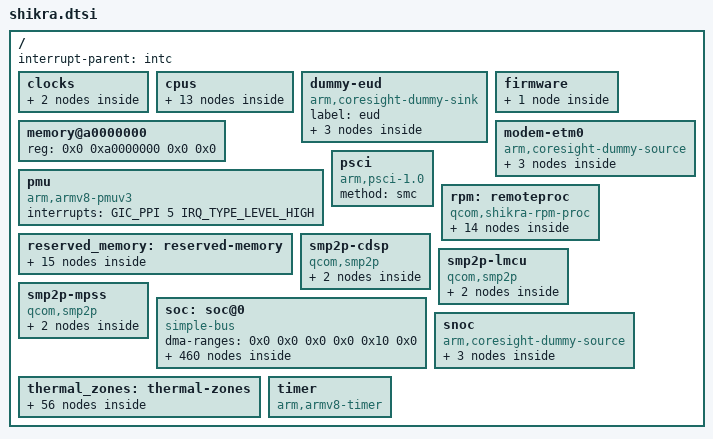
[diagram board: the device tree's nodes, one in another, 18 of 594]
// SPDX-License-Identifier: BSD-3-Clause
/*
 * Copyright (c) Qualcomm Technologies, Inc. and/or its subsidiaries.
 */

#include <dt-bindings/clock/qcom,rpmcc.h>
#include <dt-bindings/clock/qcom,dsi-phy-28nm.h>
#include <dt-bindings/clock/qcom,shikra-dispcc.h>
#include <dt-bindings/clock/qcom,shikra-gcc.h>
#include <dt-bindings/clock/qcom,shikra-gpucc.h>
#include <dt-bindings/interconnect/qcom,icc.h>
#include <dt-bindings/dma/qcom-gpi.h>
#include <dt-bindings/interconnect/qcom,rpm-icc.h>
#include <dt-bindings/interconnect/qcom,shikra.h>
#include <dt-bindings/interrupt-controller/arm-gic.h>
#include <dt-bindings/power/qcom-rpmpd.h>
#include <dt-bindings/thermal/thermal.h>

/ {
	interrupt-parent = <&intc>;

	#address-cells = <2>;
	#size-cells = <2>;

	clocks {
		xo_board: xo-board {
			compatible = "fixed-clock";
			clock-frequency = <38400000>;
			#clock-cells = <0>;
		};

		sleep_clk: sleep-clk {
			compatible = "fixed-clock";
			clock-frequency = <32764>;
			#clock-cells = <0>;
		};
	};

	cpus {
		#address-cells = <2>;
		#size-cells = <0>;

		cpu0: cpu@0 {
			device_type = "cpu";
			compatible = "arm,cortex-a55";
			reg = <0x0 0x0>;
			enable-method = "psci";
			next-level-cache = <&l3>;
			capacity-dmips-mhz = <1024>;
			dynamic-power-coefficient = <100>;
			qcom,freq-domain = <&cpufreq_hw 0>;
			#cooling-cells = <2>;
		};

		cpu1: cpu@100 {
			device_type = "cpu";
			compatible = "arm,cortex-a55";
			reg = <0x0 0x100>;
			enable-method = "psci";
			next-level-cache = <&l3>;
			capacity-dmips-mhz = <1024>;
			dynamic-power-coefficient = <100>;
			qcom,freq-domain = <&cpufreq_hw 0>;
			#cooling-cells = <2>;
		};

		cpu2: cpu@200 {
			device_type = "cpu";
			compatible = "arm,cortex-a55";
			reg = <0x0 0x200>;
			enable-method = "psci";
			next-level-cache = <&l3>;
			capacity-dmips-mhz = <1024>;
			dynamic-power-coefficient = <100>;
			qcom,freq-domain = <&cpufreq_hw 0>;
			#cooling-cells = <2>;
		};

		cpu3: cpu@300 {
			device_type = "cpu";
			compatible = "arm,cortex-a78c";
			reg = <0x0 0x300>;
			enable-method = "psci";
			next-level-cache = <&l2_3>;
			capacity-dmips-mhz = <1946>;
			dynamic-power-coefficient = <486>;
			qcom,freq-domain = <&cpufreq_hw 1>;
			#cooling-cells = <2>;

			l2_3: l2-cache {
				compatible = "cache";
				cache-level = <2>;
				cache-unified;
				next-level-cache = <&l3>;
			};
		};

		cpu-map {
			cluster0 {
				core0 {
					cpu = <&cpu0>;
				};

				core1 {
					cpu = <&cpu1>;
				};

				core2 {
					cpu = <&cpu2>;
				};
			};

			cluster1 {
				core0 {
					cpu = <&cpu3>;
				};
			};
		};

		l3: l3-cache {
			compatible = "cache";
			cache-level = <3>;
			cache-unified;
		};
	};

	dummy-eud {
		compatible = "arm,coresight-dummy-sink";

		label = "eud";

		in-ports {
			port {
				eud_in: endpoint {
					remote-endpoint = <&replicator_eud_out1>;
				};
			};
		};
	};

	firmware {
		scm {
			compatible = "qcom,scm-shikra", "qcom,scm";
			qcom,dload-mode = <&tcsr_regs 0x13000>;
			interconnects = <&system_noc MASTER_CRYPTO_CORE0 RPM_ALWAYS_TAG
					 &mc_virt SLAVE_EBI_CH0 RPM_ALWAYS_TAG>;
		};
	};

	memory@a0000000 {
		device_type = "memory";
		/* We expect the bootloader to fill in the size */
		reg = <0x0 0xa0000000 0x0 0x0>;
	};

	modem-etm0 {
		compatible = "arm,coresight-dummy-source";

		label = "modem_etm0";
		arm,static-trace-id = <36>;

		out-ports {
			port {
				modem_etm0_out: endpoint {
					remote-endpoint = <&funnel_in1_in4>;
				};
			};
		};
	};

	pmu {
		compatible = "arm,armv8-pmuv3";
		interrupts = <GIC_PPI 5 IRQ_TYPE_LEVEL_HIGH>;
	};

	psci {
		compatible = "arm,psci-1.0";
		method = "smc";
	};

	rpm: remoteproc {
		compatible = "qcom,shikra-rpm-proc", "qcom,rpm-proc";

		glink-edge {
			compatible = "qcom,glink-rpm";
			interrupts = <GIC_SPI 194 IRQ_TYPE_EDGE_RISING>;
			qcom,rpm-msg-ram = <&rpm_msg_ram>;
			mboxes = <&apcs_glb 0>;

			rpm_requests: rpm-requests {
				compatible = "qcom,rpm-shikra", "qcom,glink-smd-rpm";
				qcom,glink-channels = "rpm_requests";

				rpmcc: clock-controller {
					compatible = "qcom,rpmcc-shikra", "qcom,rpmcc";
					clocks = <&xo_board>;
					clock-names = "xo";
					#clock-cells = <1>;
				};

				rpmpd: power-controller {
					compatible = "qcom,shikra-rpmpd";
					#power-domain-cells = <1>;
					operating-points-v2 = <&rpmpd_opp_table>;

					rpmpd_opp_table: opp-table {
						compatible = "operating-points-v2";

						rpmpd_opp_min_svs: opp1 {
							opp-level = <RPM_SMD_LEVEL_MIN_SVS>;
						};

						rpmpd_opp_low_svs: opp2 {
							opp-level = <RPM_SMD_LEVEL_LOW_SVS>;
						};

						rpmpd_opp_svs: opp3 {
							opp-level = <RPM_SMD_LEVEL_SVS>;
						};

						rpmpd_opp_svs_plus: opp4 {
							opp-level = <RPM_SMD_LEVEL_SVS_PLUS>;
						};

						rpmpd_opp_nom: opp5 {
							opp-level = <RPM_SMD_LEVEL_NOM>;
						};

						rpmpd_opp_nom_plus: opp6 {
							opp-level = <RPM_SMD_LEVEL_NOM_PLUS>;
						};

						rpmpd_opp_turbo: opp7 {
							opp-level = <RPM_SMD_LEVEL_TURBO>;
						};

						rpmpd_opp_turbo_plus: opp8 {
							opp-level = <RPM_SMD_LEVEL_TURBO_NO_CPR>;
						};
					};
				};
			};
		};

		mpm: interrupt-controller {
			compatible = "qcom,mpm";
			qcom,rpm-msg-ram = <&apss_mpm>;
			interrupts = <GIC_SPI 197 IRQ_TYPE_EDGE_RISING>;
			mboxes = <&apcs_glb 1>;
			interrupt-controller;
			#interrupt-cells = <2>;
			#power-domain-cells = <0>;
			interrupt-parent = <&intc>;
			qcom,mpm-pin-count = <96>;
			qcom,mpm-pin-map = <2 275>,  /* TSENS0 uplow */
					   <12 422>, /* DWC3 ss_phy_irq */
					   <58 272>, /* QUSB2_PHY dmse_hv_vddmx */
					   <59 273>, /* QUSB2_PHY dpse_hv_vddmx */
					   <86 183>, /* MPM wake, SPMI */
					   <90 157>, /* QUSB2_PHY DM */
					   <91 158>; /* QUSB2_PHY DP */
		};
	};

	reserved_memory: reserved-memory {
		#address-cells = <2>;
		#size-cells = <2>;
		ranges;

		hyp_mem: hyp@80000000 {
			reg = <0x0 0x80000000 0x0 0x1600000>;
			no-map;
		};

		xblboot_mem: xblboot@85e00000 {
			reg = <0x0 0x85e00000 0x0 0x100000>;
			no-map;
		};

		secdata_apss_mem: secdata-apss@85fff000 {
			reg = <0x0 0x85fff000 0x0 0x1000>;
			no-map;
		};

		smem_mem: smem_region@86000000 {
			compatible = "qcom,smem";
			reg = <0x0 0x86000000 0x0 0x200000>;
			no-map;

			hwlocks = <&tcsr_mutex 3>;
		};

		audio_heap_mem: audio-heap@86200000 {
			reg = <0x0 0x86200000 0x0 0x100000>;
			no-map;
		};

		tz_stat_mem: tz-stat@a0000000 {
			reg = <0x0 0xa0000000 0x0 0x100000>;
			no-map;
		};

		qtee_mem: qtee@a1300000 {
			reg = <0x0 0xa1300000 0x0 0x500000>;
			no-map;
		};

		tz_apps_mem: tz-apps@a1800000 {
			reg = <0x0 0xa1800000 0x0 0x2100000>;
			no-map;
		};

		mpss_wlan_mem: mpss-wlan@ab000000 {
			reg = <0x0 0xab000000 0x0 0x6e00000>;
			no-map;
		};

		wlan_mem: wlan@b2300000 {
			reg = <0x0 0xb2300000 0x0 0x100000>;
			no-map;
		};

		cdsp_mem: cdsp@b2400000 {
			reg = <0x0 0xb2400000 0x0 0x1900000>;
			no-map;
		};

		gpu_micro_code_mem: gpu-micro-code@b3d00000 {
			reg = <0x0 0xb3d00000 0x0 0x2000>;
			no-map;
		};

		video_mem: video@b3d02000 {
			reg = <0x0 0xb3d02000 0x0 0x700000>;
			no-map;
		};

		lmcu_mem: lmcu@b4402000 {
			reg = <0x0 0xb4402000 0x0 0x300000>;
			no-map;
		};

		lmcu_dtb_mem: lmcu-dtb@b4702000 {
			reg = <0x0 0xb4702000 0x0 0x40000>;
			no-map;
		};

	};

	smp2p-cdsp {
		compatible = "qcom,smp2p";
		qcom,smem = <94>, <432>;

		interrupts = <GIC_SPI 263 IRQ_TYPE_EDGE_RISING>;

		mboxes = <&apcs_glb 6>;

		qcom,local-pid = <0>;
		qcom,remote-pid = <5>;

		cdsp_smp2p_out: master-kernel {
			qcom,entry-name = "master-kernel";
			#qcom,smem-state-cells = <1>;
		};

		cdsp_smp2p_in: slave-kernel {
			qcom,entry-name = "slave-kernel";
			interrupt-controller;
			#interrupt-cells = <2>;
		};
	};

	smp2p-lmcu {
		compatible = "qcom,smp2p";
		qcom,smem = <617>, <616>;

		interrupts = <GIC_SPI 287 IRQ_TYPE_EDGE_RISING>;

		mboxes = <&apcs_glb 10>;

		qcom,local-pid = <0>;
		qcom,remote-pid = <26>;

		lmcu_smp2p_out: master-kernel {
			qcom,entry-name = "master-kernel";
			#qcom,smem-state-cells = <1>;
		};

		lmcu_smp2p_in: slave-kernel {
			qcom,entry-name = "slave-kernel";
			interrupt-controller;
			#interrupt-cells = <2>;
		};
	};

	smp2p-mpss {
		compatible = "qcom,smp2p";
		qcom,smem = <435>, <428>;

		interrupts = <GIC_SPI 70 IRQ_TYPE_EDGE_RISING>;

		mboxes = <&apcs_glb 14>;

		qcom,local-pid = <0>;
		qcom,remote-pid = <1>;

		modem_smp2p_out: master-kernel {
			qcom,entry-name = "master-kernel";
			#qcom,smem-state-cells = <1>;
		};

		modem_smp2p_in: slave-kernel {
			qcom,entry-name = "slave-kernel";
			interrupt-controller;
			#interrupt-cells = <2>;
		};
	};

	soc: soc@0 {
		compatible = "simple-bus";

		#address-cells = <2>;
		#size-cells = <2>;
		dma-ranges = <0x0 0x0 0x0 0x0 0x10 0x0>;
		ranges = <0x0 0x0 0x0 0x0 0x10 0x0>;

		tcsr_mutex: syscon@340000 {
			compatible = "qcom,tcsr-mutex";
			reg = <0x0 0x00340000 0x0 0x20000>;
			#hwlock-cells = <1>;
		};

		tcsr_regs: syscon@3c0000 {
			compatible = "qcom,shikra-tcsr", "syscon";
			reg = <0x0 0x003c0000 0x0 0x40000>;
		};

		tlmm: pinctrl@500000 {
			compatible = "qcom,shikra-tlmm";
			reg = <0x0 0x00500000 0x0 0x800000>;

			interrupts = <GIC_SPI 227 IRQ_TYPE_LEVEL_HIGH>;

			gpio-controller;
			#gpio-cells = <2>;

			interrupt-controller;
			#interrupt-cells = <2>;

			gpio-ranges = <&tlmm 0 0 165>;
			wakeup-parent = <&mpm>;

			qup_i2c0_data_clk: qup-i2c0-data-clk-state {
				/* SDA, SCL */
				pins = "gpio2", "gpio3";
				function = "qup0_se0";
				drive-strength = <2>;
				bias-pull-up;
			};

			qup_i2c1_data_clk: qup-i2c1-data-clk-state {
				/* SDA, SCL */
				pins = "gpio4", "gpio5";
				function = "qup0_se1_01";
				drive-strength = <2>;
				bias-pull-up;
			};

			qup_i2c2_data_clk: qup-i2c2-data-clk-state {
				/* SDA, SCL */
				pins = "gpio6", "gpio7";
				function = "qup0_se2";
				drive-strength = <2>;
				bias-pull-up;
			};

			qup_i2c3_data_clk: qup-i2c3-data-clk-state {
				/* SDA, SCL */
				pins = "gpio10", "gpio11";
				function = "qup0_se3_01";
				drive-strength = <2>;
				bias-pull-up;
			};

			qup_i2c4_data_clk: qup-i2c4-data-clk-state {
				/* SDA, SCL */
				pins = "gpio12", "gpio13";
				function = "qup0_se4_01";
				drive-strength = <2>;
				bias-pull-up;
			};

			qup_i2c5_data_clk: qup-i2c5-data-clk-state {
				/* SDA, SCL */
				pins = "gpio14", "gpio15";
				function = "qup0_se5";
				drive-strength = <2>;
				bias-pull-up;
			};

			qup_i2c6_data_clk: qup-i2c6-data-clk-state {
				/* SDA, SCL */
				pins = "gpio18", "gpio19";
				function = "qup0_se6";
				drive-strength = <2>;
				bias-pull-up;
			};

			qup_i2c7_data_clk: qup-i2c7-data-clk-state {
				/* SDA, SCL */
				pins = "gpio20", "gpio21";
				function = "qup0_se7_01";
				drive-strength = <2>;
				bias-pull-up;
			};

			qup_i2c8_data_clk: qup-i2c8-data-clk-state {
				/* SDA, SCL */
				pins = "gpio22", "gpio23";
				function = "qup0_se8";
				drive-strength = <2>;
				bias-pull-up;
			};

			qup_i2c9_data_clk: qup-i2c9-data-clk-state {
				/* SDA, SCL */
				pins = "gpio27", "gpio26";
				function = "qup0_se9_01";
				drive-strength = <2>;
				bias-pull-up;
			};

			qup_spi0_cs: qup-spi0-cs-state {
				pins = "gpio1";
				function = "qup0_se0";
				drive-strength = <6>;
				bias-disable;
			};

			qup_spi0_data_clk: qup-spi0-data-clk-state {
				/* MISO, MOSI, CLK */
				pins = "gpio2", "gpio3", "gpio0";
				function = "qup0_se0";
				drive-strength = <6>;
				bias-disable;
			};

			qup_spi2_cs: qup-spi2-cs-state {
				pins = "gpio9";
				function = "qup0_se2";
				drive-strength = <6>;
				bias-disable;
			};

			qup_spi2_data_clk: qup-spi2-data-clk-state {
				/* MISO, MOSI, CLK */
				pins = "gpio6", "gpio7", "gpio8";
				function = "qup0_se2";
				drive-strength = <6>;
				bias-disable;
			};

			qup_spi5_cs: qup-spi5-cs-state {
				pins = "gpio17";
				function = "qup0_se5";
				drive-strength = <6>;
				bias-disable;
			};

			qup_spi5_data_clk: qup-spi5-data-clk-state {
				/* MISO, MOSI, CLK */
				pins = "gpio14", "gpio15", "gpio16";
				function = "qup0_se5";
				drive-strength = <6>;
				bias-disable;
			};

			qup_spi6_cs: qup-spi6-cs-state {
				pins = "gpio29";
				function = "qup0_se6";
				drive-strength = <6>;
				bias-disable;
			};

			qup_spi6_data_clk: qup-spi6-data-clk-state {
				/* MISO, MOSI, CLK */
				pins = "gpio18", "gpio19", "gpio28";
				function = "qup0_se6";
				drive-strength = <6>;
				bias-disable;
			};

			qup_spi8_cs: qup-spi8-cs-state {
				pins = "gpio25";
				function = "qup0_se8";
				drive-strength = <6>;
				bias-disable;
			};

			qup_spi8_data_clk: qup-spi8-data-clk-state {
				/* MISO, MOSI, CLK */
				pins = "gpio22", "gpio23", "gpio24";
				function = "qup0_se8";
				drive-strength = <6>;
				bias-disable;
			};

			qup_uart0_default: qup-uart0-default-state {
				pins = "gpio0", "gpio1";
				function = "qup0_se0";
				drive-strength = <2>;
				bias-disable;
			};

			qup_uart1_default: qup-uart1-default-state {
				pins = "gpio4", "gpio5";
				function = "qup0_se1_23";
				drive-strength = <2>;
				bias-disable;
			};

			qup_uart2_default: qup-uart2-default-state {
				/* TX, RX */
				pins = "gpio8", "gpio9";
				function = "qup0_se2";
				drive-strength = <2>;
				bias-pull-up;
			};

			qup_uart2_cts_rts: qup-uart2-cts-rts-state {
				/* CTS, RTS */
				pins = "gpio6", "gpio7";
				function = "qup0_se2";
				drive-strength = <2>;
				bias-pull-down;
			};

			qup_uart3_default: qup-uart3-default-state {
				pins = "gpio10", "gpio11";
				function = "qup0_se3_23";
				drive-strength = <2>;
				bias-disable;
			};

			qup_uart4_default: qup-uart4-default-state {
				pins = "gpio12", "gpio13";
				function = "qup0_se4_23";
				drive-strength = <2>;
				bias-disable;
			};

			qup_uart5_default: qup-uart5-default-state {
				/* TX, RX */
				pins = "gpio16", "gpio17";
				function = "qup0_se5";
				drive-strength = <2>;
				bias-pull-up;
			};

			qup_uart5_cts_rts: qup-uart5-cts-rts-state {
				/* CTS, RTS */
				pins = "gpio14", "gpio15";
				function = "qup0_se5";
				drive-strength = <2>;
				bias-pull-down;
			};

			qup_uart6_default: qup-uart6-default-state {
				/* TX, RX */
				pins = "gpio28", "gpio29";
				function = "qup0_se6";
				drive-strength = <2>;
				bias-pull-up;
			};

			qup_uart6_cts_rts: qup-uart6-cts-rts-state {
				/* CTS, RTS */
				pins = "gpio18", "gpio19";
				function = "qup0_se6";
				drive-strength = <2>;
				bias-pull-down;
			};

			qup_uart7_default: qup-uart7-default-state {
				pins = "gpio20", "gpio21";
				function = "qup0_se7_23";
				drive-strength = <2>;
				bias-disable;
			};

			qup_uart8_default: qup-uart8-default-state {
				/* TX, RX */
				pins = "gpio24", "gpio25";
				function = "qup0_se8";
				drive-strength = <2>;
				bias-pull-up;
			};

			qup_uart8_cts_rts: qup-uart8-cts-rts-state {
				/* CTS, RTS */
				pins = "gpio22", "gpio23";
				function = "qup0_se8";
				drive-strength = <2>;
				bias-pull-down;
			};

			qup_uart9_default: qup-uart9-default-state {
				pins = "gpio26", "gpio27";
				function = "qup0_se9_23";
				drive-strength = <2>;
				bias-disable;
			};

			sdc1_state_on: sdc1-on-state {
				clk-pins {
					pins = "sdc1_clk";
					drive-strength = <6>;
					bias-disable;
				};

				cmd-pins {
					pins = "sdc1_cmd";
					drive-strength = <6>;
					bias-pull-up;
				};

				data-pins {
					pins = "sdc1_data";
					drive-strength = <6>;
					bias-pull-up;
				};

				rclk-pins {
					pins = "sdc1_rclk";
					bias-pull-down;
				};
			};

			sdc1_state_off: sdc1-off-state {
				clk-pins {
					pins = "sdc1_clk";
					drive-strength = <2>;
					bias-bus-hold;
				};

				cmd-pins {
					pins = "sdc1_cmd";
					drive-strength = <2>;
					bias-bus-hold;
				};

				data-pins {
					pins = "sdc1_data";
					drive-strength = <2>;
					bias-bus-hold;
				};

				rclk-pins {
					pins = "sdc1_rclk";
					bias-bus-hold;
				};
			};

			sdc2_default: sdc2-default-state {
				clk-pins {
					pins = "sdc2_clk";
					drive-strength = <14>;
					bias-disable;
				};

				cmd-pins {
					pins = "sdc2_cmd";
					drive-strength = <14>;
					bias-pull-up;
				};

				data-pins {
					pins = "sdc2_data";
					drive-strength = <14>;
					bias-pull-up;
				};
			};

			sdc2_sleep: sdc2-sleep-state {
				clk-pins {
					pins = "sdc2_clk";
					drive-strength = <2>;
					bias-disable;
				};

				cmd-pins {
					pins = "sdc2_cmd";
					drive-strength = <2>;
					bias-pull-up;
				};

				data-pins {
					pins = "sdc2_data";
					drive-strength = <2>;
					bias-pull-up;
				};
			};

			sdc2_card_det_n: sd-card-det-n-state {
				pins = "gpio89";
				function = "gpio";
				drive-strength = <2>;
				bias-pull-up;
			};
		};

		mem_noc: interconnect@d00000 {
			compatible = "qcom,shikra-mem-noc-core";
			reg = <0x0 0x00d00000 0x0 0x43080>;
			clocks = <&gcc GCC_DDRSS_GPU_AXI_CLK>;
			clock-names = "gpu_axi";
			#interconnect-cells = <2>;
		};

		llcc: system-cache-controller@e00000 {
			compatible = "qcom,shikra-llcc";
			reg = <0x0 0x00e00000 0x0 0x80000>,
			      <0x0 0x0f00000 0x0 0x80000>,
			      <0x0 0x1000000 0x0 0x80000>;
			reg-names = "llcc0_base", "llcc1_base", "llcc_broadcast_base";
			interrupts = <GIC_SPI 571 IRQ_TYPE_LEVEL_HIGH>;
		};

		gcc: clock-controller@1400000 {
			compatible = "qcom,shikra-gcc";
			reg = <0x0 0x01400000 0x0 0x1f0000>;
			clocks = <&rpmcc RPM_SMD_XO_CLK_SRC>,
				 <&sleep_clk>,
				 <0>,
				 <0>,
				 <0>,
				 <0>,
				 <0>,
				 <0>;
			power-domains = <&rpmpd RPMPD_VDDCX>;
			#clock-cells = <1>;
			#reset-cells = <1>;
			#power-domain-cells = <1>;
		};

		usb_1_hsphy: phy@1613000 {
			compatible = "qcom,shikra-qusb2-phy";
			reg = <0x0 0x01613000 0x0 0x180>;

			clocks = <&gcc GCC_AHB2PHY_USB_CLK>,
				 <&rpmcc RPM_SMD_XO_CLK_SRC>;
			clock-names = "cfg_ahb", "ref";

			resets = <&gcc GCC_QUSB2PHY_PRIM_BCR>;
			nvmem-cells = <&qusb2_hstx_trim_1>;
			#phy-cells = <0>;

			status = "disabled";
		};

		usb_qmpphy: phy@1615000 {
			compatible = "qcom,shikra-qmp-usb3-phy";
			reg = <0x0 0x01615000 0x0 0x1000>;

			clocks = <&gcc GCC_AHB2PHY_USB_CLK>,
				 <&gcc GCC_USB3_PRIM_CLKREF_EN>,
				 <&gcc GCC_USB3_PRIM_PHY_COM_AUX_CLK>,
				 <&gcc GCC_USB3_PRIM_PHY_PIPE_CLK>;
			clock-names = "cfg_ahb",
				      "ref",
				      "com_aux",
				      "pipe";

			resets = <&gcc GCC_USB3_PHY_PRIM_SP0_BCR>,
				 <&gcc GCC_USB3PHY_PHY_PRIM_SP0_BCR>;
			reset-names = "phy",
				      "phy_phy";

			#clock-cells = <0>;
			clock-output-names = "usb3_phy_pipe_clk_src";

			#phy-cells = <0>;
			orientation-switch;

			qcom,tcsr-reg = <&tcsr_regs 0xb244>;

			status = "disabled";

			ports {
				#address-cells = <1>;
				#size-cells = <0>;

				port@0 {
					reg = <0>;

					usb_qmpphy_out: endpoint {
					};
				};

				port@1 {
					reg = <1>;

					usb_qmpphy_usb_ss_in: endpoint {
						remote-endpoint = <&usb_1_dwc3_ss>;
					};
				};
			};
		};

		system_noc: interconnect@1880000 {
			compatible = "qcom,shikra-sys-noc";
			reg = <0x0 0x01880000 0x0 0x6a080>;
			clocks = <&gcc GCC_EMAC0_AXI_SYS_NOC_CLK>,
				 <&gcc GCC_EMAC1_AXI_SYS_NOC_CLK>,
				 <&gcc GCC_SYS_NOC_USB2_PRIM_AXI_CLK>,
				 <&gcc GCC_SYS_NOC_USB3_PRIM_AXI_CLK>;
			clock-names = "emac0_axi",
				      "emac1_axi",
				      "usb2_axi",
				      "usb3_axi";
			#interconnect-cells = <2>;

			clk_virt: interconnect-clk {
				compatible = "qcom,shikra-clk-virt";
				#interconnect-cells = <2>;
			};

			mc_virt: interconnect-mc {
				compatible = "qcom,shikra-mc-virt";
				#interconnect-cells = <2>;
			};

			mmrt_virt: interconnect-mmrt {
				compatible = "qcom,shikra-mmrt-virt";
				#interconnect-cells = <2>;
			};

			mmnrt_virt: interconnect-mmnrt {
				compatible = "qcom,shikra-mmnrt-virt";
				#interconnect-cells = <2>;
			};
		};

		config_noc: interconnect@1900000 {
			compatible = "qcom,shikra-config-noc";
			reg = <0x0 0x01900000 0x0 0x8080>;
			#interconnect-cells = <2>;
		};

		cryptobam: dma-controller@1b04000 {
			compatible = "qcom,bam-v1.7.4", "qcom,bam-v1.7.0";
			reg = <0x0 0x01b04000 0x0 0x24000>;
			interrupts = <GIC_SPI 247 IRQ_TYPE_LEVEL_HIGH>;
			#dma-cells = <1>;
			iommus = <&apps_smmu 0x84 0x0011>,
				 <&apps_smmu 0x86 0x0011>,
				 <&apps_smmu 0x92 0x0>,
				 <&apps_smmu 0x94 0x0011>,
				 <&apps_smmu 0x96 0x0011>,
				 <&apps_smmu 0x98 0x0001>,
				 <&apps_smmu 0x9F 0x0>;
			qcom,ee = <0>;
			qcom,controlled-remotely;
			num-channels = <16>;
			qcom,num-ees = <4>;
		};

		crypto: crypto@1b3a000 {
			compatible = "qcom,shikra-qce", "qcom,sm8150-qce", "qcom,qce";
			reg = <0x0 0x01b3a000 0x0 0x6000>;
			dmas = <&cryptobam 4>, <&cryptobam 5>;
			dma-names = "rx", "tx";
			iommus = <&apps_smmu 0x84 0x0011>,
				 <&apps_smmu 0x86 0x0011>,
				 <&apps_smmu 0x92 0x0>,
				 <&apps_smmu 0x94 0x0011>,
				 <&apps_smmu 0x96 0x0011>,
				 <&apps_smmu 0x98 0x0001>,
				 <&apps_smmu 0x9F 0x0>;
			interconnects = <&system_noc MASTER_CRYPTO_CORE0 0
					 &mc_virt SLAVE_EBI_CH0 0>;
			interconnect-names = "memory";
		};

		qfprom: efuse@1b40000 {
			compatible = "qcom,shikra-qfprom", "qcom,qfprom";
			reg = <0x0 0x01b40000 0x0 0x700>;
			#address-cells = <1>;
			#size-cells = <1>;

			qusb2_hstx_trim_1: hstx-trim@258 {
				reg = <0x25b 0x1>;
				bits = <1 4>;
			};

			gpu_speed_bin: gpu-speed-bin@6006 {
				reg = <0x6006 0x2>;
				bits = <5 8>;
			};
		};

		spmi_bus: spmi@1c40000 {
			compatible = "qcom,spmi-pmic-arb";
			reg = <0x0 0x01c40000 0x0 0x1100>,
			      <0x0 0x01e00000 0x0 0x2000000>,
			      <0x0 0x03e00000 0x0 0x100000>,
			      <0x0 0x03f00000 0x0 0xa0000>,
			      <0x0 0x01c0a000 0x0 0x26000>;
			reg-names = "core",
				    "chnls",
				    "obsrvr",
				    "intr",
				    "cnfg";
			interrupts-extended = <&mpm 86 IRQ_TYPE_EDGE_RISING>;
			interrupt-names = "periph_irq";
			interrupt-controller;
			#interrupt-cells = <4>;
			#address-cells = <2>;
			#size-cells = <0>;
			qcom,channel = <0>;
			qcom,ee = <0>;
		};

		tsens0: thermal-sensor@4411000 {
			compatible = "qcom,shikra-tsens", "qcom,tsens-v2";
			reg = <0x0 0x04411000 0x0 0x1000>,
			      <0x0 0x04410000 0x0 0x1000>;
			interrupts = <GIC_SPI 275 IRQ_TYPE_LEVEL_HIGH>,
				     <GIC_SPI 190 IRQ_TYPE_LEVEL_HIGH>;
			interrupt-names = "uplow",
					  "critical";
			#qcom,sensors = <14>;
			#thermal-sensor-cells = <1>;
		};

		rng: rng@4454000 {
			compatible = "qcom,shikra-trng", "qcom,trng";
			reg = <0 0x04454000 0 0x1000>;
		};

		rpm_msg_ram: sram@45f0000 {
			compatible = "qcom,rpm-msg-ram", "mmio-sram";
			reg = <0x0 0x045f0000 0x0 0x7000>;

			#address-cells = <1>;
			#size-cells = <1>;
			ranges = <0 0x0 0x045f0000 0x7000>;

			apss_mpm: sram@1b8 {
				reg = <0x1b8 0x48>;
			};
		};

		sram@4690000 {
			compatible = "qcom,rpm-stats";
			reg = <0x0 0x04690000 0x0 0x14000>;
		};

		sdhc_1: mmc@4744000 {
			compatible = "qcom,shikra-sdhci", "qcom,sdhci-msm-v5";

			reg = <0x0 0x04744000 0x0 0x1000>,
			      <0x0 0x04745000 0x0 0x1000>;
			reg-names = "hc",
				    "cqhci";

			iommus = <&apps_smmu 0xc0 0x0>;

			interrupts = <GIC_SPI 348 IRQ_TYPE_LEVEL_HIGH>,
				     <GIC_SPI 352 IRQ_TYPE_LEVEL_HIGH>;
			interrupt-names = "hc_irq",
					  "pwr_irq";

			clocks = <&gcc GCC_SDCC1_AHB_CLK>,
				 <&gcc GCC_SDCC1_APPS_CLK>,
				 <&rpmcc RPM_SMD_XO_CLK_SRC>;
			clock-names = "iface",
				      "core",
				      "xo";

			interconnects = <&system_noc MASTER_SDCC_1 QCOM_ICC_TAG_ALWAYS
					&mc_virt SLAVE_EBI_CH0 QCOM_ICC_TAG_ALWAYS>,
					<&mem_noc MASTER_AMPSS_M0 QCOM_ICC_TAG_ACTIVE_ONLY
					&config_noc SLAVE_SDCC_1 QCOM_ICC_TAG_ACTIVE_ONLY>;
			interconnect-names = "sdhc-ddr",
					     "cpu-sdhc";

			power-domains = <&rpmpd RPMHPD_CX>;
			operating-points-v2 = <&sdhc1_opp_table>;

			qcom,dll-config = <0x000f642c>;
			qcom,ddr-config = <0x80040868>;

			bus-width = <8>;

			mmc-ddr-1_8v;
			mmc-hs200-1_8v;
			mmc-hs400-1_8v;
			mmc-hs400-enhanced-strobe;

			resets = <&gcc GCC_SDCC1_BCR>;
			qcom,ice = <&sdhc_ice>;

			status = "disabled";

			sdhc1_opp_table: opp-table-1 {
				compatible = "operating-points-v2";

				opp-100000000 {
					opp-hz = /bits/ 64 <100000000>;
					required-opps = <&rpmpd_opp_low_svs>;
					opp-peak-kBps = <250000 133320>;
					opp-avg-kBps = <104000 0>;
				};

				opp-384000000 {
					opp-hz = /bits/ 64 <384000000>;
					required-opps = <&rpmpd_opp_nom>;
					opp-peak-kBps = <800000 300000>;
					opp-avg-kBps = <400000 0>;
				};
			};
		};

		sdhc_2: mmc@4784000 {
			compatible = "qcom,shikra-sdhci", "qcom,sdhci-msm-v5";
			reg = <0x0 0x4784000 0x0 0x1000>;

			interrupts = <GIC_SPI 350 IRQ_TYPE_LEVEL_HIGH>,
				     <GIC_SPI 353 IRQ_TYPE_LEVEL_HIGH>;
			interrupt-names = "hc_irq", "pwr_irq";

			bus-width = <4>;

			clocks = <&gcc GCC_SDCC2_AHB_CLK>,
					 <&gcc GCC_SDCC2_APPS_CLK>,
					 <&rpmcc RPM_SMD_XO_CLK_SRC>;
			clock-names = "iface", "core", "xo";

			qcom,dll-config = <0x0007442c>;
			qcom,ddr-config = <0x80040868>;

			iommus = <&apps_smmu 0x0a0 0x0>;

			interconnects = <&system_noc MASTER_SDCC_2 QCOM_ICC_TAG_ALWAYS
					&mc_virt SLAVE_EBI_CH0 QCOM_ICC_TAG_ALWAYS>,
					<&mem_noc MASTER_AMPSS_M0 QCOM_ICC_TAG_ACTIVE_ONLY
					&config_noc SLAVE_SDCC_2 QCOM_ICC_TAG_ACTIVE_ONLY>;
			interconnect-names = "sdhc-ddr","cpu-sdhc";
			operating-points-v2 = <&sdhc2_opp_table>;

			status = "disabled";

			sdhc2_opp_table: opp-table-2 {
				compatible = "operating-points-v2";

				opp-100000000 {
					opp-hz = /bits/ 64 <100000000>;
					required-opps = <&rpmpd_opp_low_svs>;
				};

				opp-202000000 {
					opp-hz = /bits/ 64 <202000000>;
					required-opps = <&rpmpd_opp_nom>;
				};
			};
		};

		usb_1: usb@4e00000 {
			compatible = "qcom,shikra-dwc3", "qcom,snps-dwc3";
			reg = <0x0 0x04e00000 0x0 0xfc100>;

			clocks = <&gcc GCC_CFG_NOC_USB3_PRIM_AXI_CLK>,
				 <&gcc GCC_USB30_PRIM_MASTER_CLK>,
				 <&gcc GCC_SYS_NOC_USB3_PRIM_AXI_CLK>,
				 <&gcc GCC_USB30_PRIM_SLEEP_CLK>,
				 <&gcc GCC_USB30_PRIM_MOCK_UTMI_CLK>,
				 <&gcc GCC_USB3_PRIM_CLKREF_EN>;
			clock-names = "cfg_noc",
				      "core",
				      "iface",
				      "sleep",
				      "mock_utmi",
				      "xo";

			assigned-clocks = <&gcc GCC_USB30_PRIM_MOCK_UTMI_CLK>,
					  <&gcc GCC_USB30_PRIM_MASTER_CLK>;
			assigned-clock-rates = <19200000>, <133333333>;

			interrupts-extended = <&intc GIC_SPI 255 IRQ_TYPE_LEVEL_HIGH>,
					      <&intc GIC_SPI 302 IRQ_TYPE_LEVEL_HIGH>,
					      <&intc GIC_SPI 260 IRQ_TYPE_LEVEL_HIGH>,
					      <&intc GIC_SPI 422 IRQ_TYPE_LEVEL_HIGH>;
			interrupt-names = "dwc_usb3",
					  "pwr_event",
					  "qusb2_phy",
					  "ss_phy_irq";

			iommus = <&apps_smmu 0x120 0x0>;

			phys = <&usb_1_hsphy>, <&usb_qmpphy>;
			phy-names = "usb2-phy", "usb3-phy";

			power-domains = <&gcc GCC_USB30_PRIM_GDSC>;

			resets = <&gcc GCC_USB30_PRIM_BCR>;

			snps,dis_u2_susphy_quirk;
			snps,dis_enblslpm_quirk;
			snps,has-lpm-erratum;
			snps,hird-threshold = /bits/ 8 <0x10>;
			snps,usb3_lpm_capable;
			snps,parkmode-disable-ss-quirk;

			usb-role-switch;

			wakeup-source;

			status = "disabled";

			ports {
				#address-cells = <1>;
				#size-cells = <0>;

				port@0 {
					reg = <0>;

					usb_1_dwc3_hs: endpoint {
					};
				};

				port@1 {
					reg = <1>;

					usb_1_dwc3_ss: endpoint {
						remote-endpoint = <&usb_qmpphy_usb_ss_in>;
					};
				};
			};
		};

		gpucc: clock-controller@5990000 {
			compatible = "qcom,shikra-gpucc";
			reg = <0x0 0x05990000 0x0 0x9000>;
			clocks = <&rpmcc RPM_SMD_XO_CLK_SRC>,
				 <&gcc GCC_GPU_GPLL0_CLK_SRC>,
				 <&gcc GCC_GPU_GPLL0_DIV_CLK_SRC>;
			#clock-cells = <1>;
			#reset-cells = <1>;
			#power-domain-cells = <1>;
		};

		adreno_smmu: iommu@59a0000 {
			compatible = "qcom,shikra-smmu-500", "qcom,adreno-smmu",
				     "qcom,smmu-500", "arm,mmu-500";
			reg = <0x0 0x059a0000 0x0 0x10000>;
			#iommu-cells = <2>;
			#global-interrupts = <1>;

			interrupts = <GIC_SPI 163 IRQ_TYPE_LEVEL_HIGH>,
				     <GIC_SPI 167 IRQ_TYPE_LEVEL_HIGH>,
				     <GIC_SPI 168 IRQ_TYPE_LEVEL_HIGH>,
				     <GIC_SPI 169 IRQ_TYPE_LEVEL_HIGH>,
				     <GIC_SPI 170 IRQ_TYPE_LEVEL_HIGH>,
				     <GIC_SPI 171 IRQ_TYPE_LEVEL_HIGH>,
				     <GIC_SPI 172 IRQ_TYPE_LEVEL_HIGH>,
				     <GIC_SPI 173 IRQ_TYPE_LEVEL_HIGH>,
				     <GIC_SPI 174 IRQ_TYPE_LEVEL_HIGH>;

			clocks = <&gpucc GPU_CC_GPU_SMMU_VOTE_CLK>,
				<&gcc GCC_GPU_MEMNOC_GFX_CLK>,
				<&gcc GCC_GPU_SNOC_DVM_GFX_CLK>,
				<&gpucc GPU_CC_AHB_CLK>;
			clock-names = "hlos",
				      "mem",
				      "iface",
				      "ahb";

			power-domains = <&gpucc GPU_CC_CX_GDSC>;
		};

		iris: video-codec@5a00000 {
			compatible = "qcom,shikra-iris", "qcom,qcm2290-venus";
			reg = <0 0x5a00000 0 0x200000>;
			interrupts = <GIC_SPI 225 IRQ_TYPE_LEVEL_HIGH>;

			power-domains = <&gcc GCC_VENUS_GDSC>,
					<&gcc GCC_VCODEC0_GDSC>,
					<&rpmpd QCM2290_VDDCX>;
			power-domain-names = "venus",
					     "vcodec0",
					     "cx";
			operating-points-v2 = <&venus_opp_table>;

			clocks = <&gcc GCC_VIDEO_VENUS_CTL_CLK>,
				 <&gcc GCC_VIDEO_AHB_CLK>,
				 <&gcc GCC_VENUS_CTL_AXI_CLK>,
				 <&gcc GCC_VIDEO_THROTTLE_CORE_CLK>,
				 <&gcc GCC_VIDEO_VCODEC0_SYS_CLK>,
				 <&gcc GCC_VCODEC0_AXI_CLK>;
			clock-names = "core",
				      "iface",
				      "bus",
				      "throttle",
				      "vcodec0_core",
				      "vcodec0_bus";

			memory-region = <&video_mem>;
			interconnects = <&mmnrt_virt MASTER_VIDEO_P0 RPM_ALWAYS_TAG
					 &mc_virt SLAVE_EBI_CH0 RPM_ALWAYS_TAG>,
					<&mem_noc MASTER_AMPSS_M0 RPM_ACTIVE_TAG
					 &config_noc SLAVE_VENUS_CFG RPM_ACTIVE_TAG>;
			interconnect-names = "video-mem",
					     "cpu-cfg";

			iommus = <&apps_smmu 0x780 0x0020>;

			venus_opp_table: opp-table {
				compatible = "operating-points-v2";

				opp-133333333 {
					opp-hz = /bits/ 64 <133333333>;
					required-opps = <&rpmpd_opp_low_svs>;
				};

				opp-240000000 {
					opp-hz = /bits/ 64 <240000000>;
					required-opps = <&rpmpd_opp_svs>;
				};

				opp-300000000 {
					opp-hz = /bits/ 64 <300000000>;
					required-opps = <&rpmpd_opp_svs_plus>;
				};

				opp-384000000 {
					opp-hz = /bits/ 64 <384000000>;
					required-opps = <&rpmpd_opp_nom>;
				};
			};
		};

		mdss: display-subsystem@5e00000 {
			compatible = "qcom,shikra-mdss";
			reg = <0x0 0x05e00000 0x0 0x1000>;
			reg-names = "mdss";
			interrupts = <GIC_SPI 186 IRQ_TYPE_LEVEL_HIGH>;
			interrupt-controller;
			#interrupt-cells = <1>;

			clocks = <&gcc GCC_DISP_AHB_CLK>,
				 <&gcc GCC_DISP_HF_AXI_CLK>,
				 <&dispcc DISP_CC_MDSS_MDP_CLK>;
			clock-names = "iface",
				      "bus",
				      "core";

			resets = <&dispcc DISP_CC_MDSS_CORE_BCR>;

			power-domains = <&dispcc DISP_CC_MDSS_CORE_GDSC>;

			iommus = <&apps_smmu 0x420 0x2>;
			interconnects = <&mmrt_virt MASTER_MDP_PORT0 RPM_ALWAYS_TAG
					 &mc_virt SLAVE_EBI_CH0 RPM_ALWAYS_TAG>,
					<&mem_noc MASTER_AMPSS_M0 RPM_ALWAYS_TAG
					 &config_noc SLAVE_DISPLAY_CFG RPM_ALWAYS_TAG>;
			interconnect-names = "mdp0-mem",
					     "cpu-cfg";

			#address-cells = <2>;
			#size-cells = <2>;
			ranges;

			status = "disabled";

			mdp: display-controller@5e01000 {
				compatible = "qcom,shikra-dpu";
				reg = <0x0 0x05e01000 0x0 0x8f000>,
				      <0x0 0x05eb0000 0x0 0x3000>;
				reg-names = "mdp",
					    "vbif";

				interrupt-parent = <&mdss>;
				interrupts = <0>;

				clocks = <&gcc GCC_DISP_HF_AXI_CLK>,
					 <&dispcc DISP_CC_MDSS_AHB_CLK>,
					 <&dispcc DISP_CC_MDSS_MDP_CLK>,
					 <&dispcc DISP_CC_MDSS_MDP_LUT_CLK>,
					 <&dispcc DISP_CC_MDSS_VSYNC_CLK>;
				clock-names = "bus",
					      "iface",
					      "core",
					      "lut",
					      "vsync";

				operating-points-v2 = <&mdp_opp_table>;
				power-domains = <&rpmpd QCM2290_VDDCX>;

				ports {
					#address-cells = <1>;
					#size-cells = <0>;

					port@0 {
						reg = <0>;
						dpu_intf1_out: endpoint {
							remote-endpoint = <&mdss_dsi0_in>;
						};
					};
				};

				mdp_opp_table: opp-table {
					compatible = "operating-points-v2";

					opp-19200000 {
						opp-hz = /bits/ 64 <19200000>;
						required-opps = <&rpmpd_opp_min_svs>;
					};

					opp-192000000 {
						opp-hz = /bits/ 64 <192000000>;
						required-opps = <&rpmpd_opp_low_svs>;
					};

					opp-256000000 {
						opp-hz = /bits/ 64 <256000000>;
						required-opps = <&rpmpd_opp_svs>;
					};

					opp-307200000 {
						opp-hz = /bits/ 64 <307200000>;
						required-opps = <&rpmpd_opp_svs_plus>;
					};

					opp-384000000 {
						opp-hz = /bits/ 64 <384000000>;
						required-opps = <&rpmpd_opp_nom>;
					};
				};
			};

			mdss_dsi0: dsi@5e94000 {
				compatible = "qcom,shikra-dsi-ctrl",
					     "qcom,mdss-dsi-ctrl";
				reg = <0x0 0x05e94000 0x0 0x400>;
				reg-names = "dsi_ctrl";

				interrupt-parent = <&mdss>;
				interrupts = <4>;

				clocks = <&dispcc DISP_CC_MDSS_BYTE0_CLK>,
					 <&dispcc DISP_CC_MDSS_BYTE0_INTF_CLK>,
					 <&dispcc DISP_CC_MDSS_PCLK0_CLK>,
					 <&dispcc DISP_CC_MDSS_ESC0_CLK>,
					 <&dispcc DISP_CC_MDSS_AHB_CLK>,
					 <&gcc GCC_DISP_HF_AXI_CLK>;
				clock-names = "byte",
					      "byte_intf",
					      "pixel",
					      "core",
					      "iface",
					      "bus";

				assigned-clocks = <&dispcc DISP_CC_MDSS_BYTE0_CLK_SRC>,
						  <&dispcc DISP_CC_MDSS_PCLK0_CLK_SRC>;
				assigned-clock-parents = <&mdss_dsi0_phy DSI_BYTE_PLL_CLK>,
							 <&mdss_dsi0_phy DSI_PIXEL_PLL_CLK>;

				operating-points-v2 = <&dsi_opp_table>;
				power-domains = <&rpmpd QCM2290_VDDCX>;
				phys = <&mdss_dsi0_phy>;

				#address-cells = <1>;
				#size-cells = <0>;

				status = "disabled";

				dsi_opp_table: opp-table {
					compatible = "operating-points-v2";

					opp-19200000 {
						opp-hz = /bits/ 64 <19200000>;
						required-opps = <&rpmpd_opp_min_svs>;
					};

					opp-164000000 {
						opp-hz = /bits/ 64 <164000000>;
						required-opps = <&rpmpd_opp_low_svs>;
					};

					opp-187500000 {
						opp-hz = /bits/ 64 <187500000>;
						required-opps = <&rpmpd_opp_svs>;
					};
				};

				ports {
					#address-cells = <1>;
					#size-cells = <0>;

					port@0 {
						reg = <0>;
						mdss_dsi0_in: endpoint {
							remote-endpoint = <&dpu_intf1_out>;
						};
					};

					port@1 {
						reg = <1>;
						mdss_dsi0_out: endpoint {
						};
					};
				};
			};

			mdss_dsi0_phy: phy@5e94400 {
				compatible = "qcom,dsi-phy-14nm-2290";
				reg = <0x0 0x05e94400 0x0 0x100>,
				      <0x0 0x05e94500 0x0 0x300>,
				      <0x0 0x05e94800 0x0 0x188>;
				reg-names = "dsi_phy",
					    "dsi_phy_lane",
					    "dsi_pll";

				clocks = <&dispcc DISP_CC_MDSS_AHB_CLK>,
					 <&rpmcc RPM_SMD_XO_CLK_SRC>;
				clock-names = "iface",
					      "ref";

				power-domains = <&rpmpd QCM2290_VDDMX>;
				required-opps = <&rpmpd_opp_nom>;

				#clock-cells = <1>;
				#phy-cells = <0>;

				status = "disabled";
			};
		};

		dispcc: clock-controller@5f00000 {
			compatible = "qcom,shikra-dispcc";
			reg = <0x0 0x05f00000 0x0 0x20000>;
			clocks = <&rpmcc RPM_SMD_XO_CLK_SRC>,
				 <&sleep_clk>,
				 <&gcc GCC_DISP_GPLL0_DIV_CLK_SRC>,
				 <&mdss_dsi0_phy DSI_BYTE_PLL_CLK>,
				 <&mdss_dsi0_phy DSI_PIXEL_PLL_CLK>,
				 <0>,
				 <0>;
			#clock-cells = <1>;
			#reset-cells = <1>;
			#power-domain-cells = <1>;
		};

		sram@c11e000 {
			compatible = "qcom,shikra-imem", "syscon", "simple-mfd";
			reg = <0x0 0x0c11e000 0x0 0x1000>;
			ranges = <0x0 0x0 0x0c11e000 0x1000>;

			#address-cells = <1>;
			#size-cells = <1>;

			pil-reloc@94c {
				compatible = "qcom,pil-reloc-info";
				reg = <0x94c 0xc8>;
			};
		};

		apps_smmu: iommu@c600000 {
			compatible = "qcom,shikra-smmu-500", "qcom,smmu-500", "arm,mmu-500";
			reg = <0x0 0x0c600000 0x0 0x80000>;
			#iommu-cells = <2>;
			#global-interrupts = <1>;

			interrupts = <GIC_SPI 81 IRQ_TYPE_LEVEL_HIGH>,
				     <GIC_SPI 87 IRQ_TYPE_LEVEL_HIGH>,
				     <GIC_SPI 88 IRQ_TYPE_LEVEL_HIGH>,
				     <GIC_SPI 89 IRQ_TYPE_LEVEL_HIGH>,
				     <GIC_SPI 90 IRQ_TYPE_LEVEL_HIGH>,
				     <GIC_SPI 91 IRQ_TYPE_LEVEL_HIGH>,
				     <GIC_SPI 92 IRQ_TYPE_LEVEL_HIGH>,
				     <GIC_SPI 93 IRQ_TYPE_LEVEL_HIGH>,
				     <GIC_SPI 94 IRQ_TYPE_LEVEL_HIGH>,
				     <GIC_SPI 95 IRQ_TYPE_LEVEL_HIGH>,
				     <GIC_SPI 96 IRQ_TYPE_LEVEL_HIGH>,
				     <GIC_SPI 97 IRQ_TYPE_LEVEL_HIGH>,
				     <GIC_SPI 98 IRQ_TYPE_LEVEL_HIGH>,
				     <GIC_SPI 99 IRQ_TYPE_LEVEL_HIGH>,
				     <GIC_SPI 100 IRQ_TYPE_LEVEL_HIGH>,
				     <GIC_SPI 101 IRQ_TYPE_LEVEL_HIGH>,
				     <GIC_SPI 102 IRQ_TYPE_LEVEL_HIGH>,
				     <GIC_SPI 103 IRQ_TYPE_LEVEL_HIGH>,
				     <GIC_SPI 104 IRQ_TYPE_LEVEL_HIGH>,
				     <GIC_SPI 105 IRQ_TYPE_LEVEL_HIGH>,
				     <GIC_SPI 106 IRQ_TYPE_LEVEL_HIGH>,
				     <GIC_SPI 107 IRQ_TYPE_LEVEL_HIGH>,
				     <GIC_SPI 108 IRQ_TYPE_LEVEL_HIGH>,
				     <GIC_SPI 109 IRQ_TYPE_LEVEL_HIGH>,
				     <GIC_SPI 110 IRQ_TYPE_LEVEL_HIGH>,
				     <GIC_SPI 111 IRQ_TYPE_LEVEL_HIGH>,
				     <GIC_SPI 112 IRQ_TYPE_LEVEL_HIGH>,
				     <GIC_SPI 113 IRQ_TYPE_LEVEL_HIGH>,
				     <GIC_SPI 114 IRQ_TYPE_LEVEL_HIGH>,
				     <GIC_SPI 115 IRQ_TYPE_LEVEL_HIGH>,
				     <GIC_SPI 116 IRQ_TYPE_LEVEL_HIGH>,
				     <GIC_SPI 117 IRQ_TYPE_LEVEL_HIGH>,
				     <GIC_SPI 118 IRQ_TYPE_LEVEL_HIGH>,
				     <GIC_SPI 119 IRQ_TYPE_LEVEL_HIGH>,
				     <GIC_SPI 120 IRQ_TYPE_LEVEL_HIGH>,
				     <GIC_SPI 121 IRQ_TYPE_LEVEL_HIGH>,
				     <GIC_SPI 122 IRQ_TYPE_LEVEL_HIGH>,
				     <GIC_SPI 123 IRQ_TYPE_LEVEL_HIGH>,
				     <GIC_SPI 124 IRQ_TYPE_LEVEL_HIGH>,
				     <GIC_SPI 125 IRQ_TYPE_LEVEL_HIGH>,
				     <GIC_SPI 126 IRQ_TYPE_LEVEL_HIGH>,
				     <GIC_SPI 127 IRQ_TYPE_LEVEL_HIGH>,
				     <GIC_SPI 128 IRQ_TYPE_LEVEL_HIGH>,
				     <GIC_SPI 129 IRQ_TYPE_LEVEL_HIGH>,
				     <GIC_SPI 130 IRQ_TYPE_LEVEL_HIGH>,
				     <GIC_SPI 131 IRQ_TYPE_LEVEL_HIGH>,
				     <GIC_SPI 132 IRQ_TYPE_LEVEL_HIGH>,
				     <GIC_SPI 133 IRQ_TYPE_LEVEL_HIGH>,
				     <GIC_SPI 134 IRQ_TYPE_LEVEL_HIGH>,
				     <GIC_SPI 135 IRQ_TYPE_LEVEL_HIGH>,
				     <GIC_SPI 136 IRQ_TYPE_LEVEL_HIGH>,
				     <GIC_SPI 137 IRQ_TYPE_LEVEL_HIGH>,
				     <GIC_SPI 138 IRQ_TYPE_LEVEL_HIGH>,
				     <GIC_SPI 139 IRQ_TYPE_LEVEL_HIGH>,
				     <GIC_SPI 140 IRQ_TYPE_LEVEL_HIGH>,
				     <GIC_SPI 141 IRQ_TYPE_LEVEL_HIGH>,
				     <GIC_SPI 142 IRQ_TYPE_LEVEL_HIGH>,
				     <GIC_SPI 143 IRQ_TYPE_LEVEL_HIGH>,
				     <GIC_SPI 144 IRQ_TYPE_LEVEL_HIGH>,
				     <GIC_SPI 145 IRQ_TYPE_LEVEL_HIGH>,
				     <GIC_SPI 146 IRQ_TYPE_LEVEL_HIGH>,
				     <GIC_SPI 147 IRQ_TYPE_LEVEL_HIGH>,
				     <GIC_SPI 148 IRQ_TYPE_LEVEL_HIGH>,
				     <GIC_SPI 149 IRQ_TYPE_LEVEL_HIGH>,
				     <GIC_SPI 150 IRQ_TYPE_LEVEL_HIGH>;
		};

		wifi: wifi@c800000 {
			compatible = "qcom,wcn3990-wifi";
			reg = <0x0 0x0c800000 0x0 0x800000>;
			reg-names = "membase";
			memory-region = <&wlan_mem>;
			interrupts = <GIC_SPI 358 IRQ_TYPE_LEVEL_HIGH>,
				     <GIC_SPI 359 IRQ_TYPE_LEVEL_HIGH>,
				     <GIC_SPI 360 IRQ_TYPE_LEVEL_HIGH>,
				     <GIC_SPI 361 IRQ_TYPE_LEVEL_HIGH>,
				     <GIC_SPI 362 IRQ_TYPE_LEVEL_HIGH>,
				     <GIC_SPI 363 IRQ_TYPE_LEVEL_HIGH>,
				     <GIC_SPI 364 IRQ_TYPE_LEVEL_HIGH>,
				     <GIC_SPI 365 IRQ_TYPE_LEVEL_HIGH>,
				     <GIC_SPI 366 IRQ_TYPE_LEVEL_HIGH>,
				     <GIC_SPI 367 IRQ_TYPE_LEVEL_HIGH>,
				     <GIC_SPI 368 IRQ_TYPE_LEVEL_HIGH>,
				     <GIC_SPI 369 IRQ_TYPE_LEVEL_HIGH>;
			iommus = <&apps_smmu 0x1a0 0x1>;
			qcom,msa-fixed-perm;

			status = "disabled";
		};

		intc: interrupt-controller@f200000 {
			compatible = "arm,gic-v3";
			reg = <0x0 0xf200000 0x0 0x10000>, /* GICD */
			      <0x0 0xf240000 0x0 0x80000>; /* GICR * 4 regions */

			interrupts = <GIC_PPI 8 IRQ_TYPE_LEVEL_HIGH>;

			#interrupt-cells = <3>;
			interrupt-controller;

			#redistributor-regions = <1>;
			redistributor-stride = <0x0 0x20000>;

			#address-cells = <2>;
			#size-cells = <2>;
			ranges;
		};

		apcs_glb: mailbox@f400000 {
			compatible = "qcom,shikra-apss-shared", "qcom,sdm845-apss-shared";
			reg = <0x0 0x0f400000 0x0 0x1000>;
			#mbox-cells = <1>;
		};

		watchdog@f410000 {
			compatible = "qcom,apss-wdt-shikra", "qcom,kpss-wdt";
			reg = <0x0 0x0f410000 0x0 0x1000>;
			interrupts = <GIC_SPI 0 IRQ_TYPE_LEVEL_HIGH>,
				     <GIC_SPI 1 IRQ_TYPE_LEVEL_HIGH>;
			clocks = <&sleep_clk>;
		};

		timer@f420000 {
			compatible = "arm,armv7-timer-mem";
			reg = <0x0 0x0f420000  0x0 0x1000>;

			#address-cells = <1>;
			#size-cells = <1>;
			ranges = <0x0 0x0 0x0 0x10000000>;

			frame@f421000 {
				reg = <0x0f421000 0x1000>,
				      <0x0f422000 0x1000>;
				frame-number = <0>;
				interrupts = <GIC_SPI 8 IRQ_TYPE_LEVEL_HIGH>,
					     <GIC_SPI 6 IRQ_TYPE_LEVEL_HIGH>;
			};

			frame@f423000 {
				reg = <0x0f423000 0x1000>;
				frame-number = <1>;
				interrupts = <GIC_SPI 9 IRQ_TYPE_LEVEL_HIGH>;
				status = "disabled";
			};

			frame@f425000 {
				reg = <0x0f425000 0x1000>;
				frame-number = <2>;
				interrupts = <GIC_SPI 10 IRQ_TYPE_LEVEL_HIGH>;
				status = "disabled";
			};

			frame@f427000 {
				reg = <0x0f427000 0x1000>;
				frame-number = <3>;
				interrupts = <GIC_SPI 11 IRQ_TYPE_LEVEL_HIGH>;
				status = "disabled";
			};

			frame@f429000 {
				reg = <0x0f429000 0x1000>;
				frame-number = <4>;
				interrupts = <GIC_SPI 12 IRQ_TYPE_LEVEL_HIGH>;
				status = "disabled";
			};

			frame@f42b000 {
				reg = <0x0f42b000 0x1000>;
				frame-number = <5>;
				interrupts = <GIC_SPI 13 IRQ_TYPE_LEVEL_HIGH>;
				status = "disabled";
			};

			frame@f42d000 {
				reg = <0x0f42d000 0x1000>;
				frame-number = <6>;
				interrupts = <GIC_SPI 14 IRQ_TYPE_LEVEL_HIGH>;
				status = "disabled";
			};
		};

		gpi_dma0: dma-controller@4a00000 {
			compatible = "qcom,shikra-gpi-dma", "qcom,sm6350-gpi-dma";
			reg = <0x0 0x04a00000 0x0 0x60000>;

			interrupts = <GIC_SPI 511 IRQ_TYPE_LEVEL_HIGH>,
				     <GIC_SPI 512 IRQ_TYPE_LEVEL_HIGH>,
				     <GIC_SPI 513 IRQ_TYPE_LEVEL_HIGH>,
				     <GIC_SPI 514 IRQ_TYPE_LEVEL_HIGH>,
				     <GIC_SPI 515 IRQ_TYPE_LEVEL_HIGH>,
				     <GIC_SPI 516 IRQ_TYPE_LEVEL_HIGH>,
				     <GIC_SPI 517 IRQ_TYPE_LEVEL_HIGH>,
				     <GIC_SPI 518 IRQ_TYPE_LEVEL_HIGH>,
				     <GIC_SPI 519 IRQ_TYPE_LEVEL_HIGH>,
				     <GIC_SPI 520 IRQ_TYPE_LEVEL_HIGH>,
				     <GIC_SPI 521 IRQ_TYPE_LEVEL_HIGH>,
				     <GIC_SPI 522 IRQ_TYPE_LEVEL_HIGH>,
				     <GIC_SPI 523 IRQ_TYPE_LEVEL_HIGH>,
				     <GIC_SPI 524 IRQ_TYPE_LEVEL_HIGH>,
				     <GIC_SPI 525 IRQ_TYPE_LEVEL_HIGH>,
				     <GIC_SPI 526 IRQ_TYPE_LEVEL_HIGH>;

			dma-channels = <16>;
			dma-channel-mask = <0xff>;
			#dma-cells = <3>;

			iommus = <&apps_smmu 0xf6 0x0>;
		};

		sdhc_ice: crypto@4748000 {
			compatible = "qcom,shikra-inline-crypto-engine",
				     "qcom,inline-crypto-engine";
			reg = <0x0 0x04748000 0x0 0x18000>;
			clocks = <&gcc GCC_SDCC1_ICE_CORE_CLK>,
				 <&gcc GCC_SDCC1_AHB_CLK>;
			clock-names = "core",
				      "iface";
			power-domains = <&rpmpd RPMHPD_CX>;
		};

		qupv3_0: geniqup@4ac0000 {
			compatible = "qcom,geni-se-qup";
			reg = <0x0 0x04ac0000 0x0 0x2000>;

			clocks = <&gcc GCC_QUPV3_WRAP_0_M_AHB_CLK>,
				 <&gcc GCC_QUPV3_WRAP_0_S_AHB_CLK>;
			clock-names = "m-ahb",
				      "s-ahb";

			iommus = <&apps_smmu 0xe3 0x0>;

			#address-cells = <2>;
			#size-cells = <2>;
			ranges;

			status = "disabled";

			i2c0: i2c@4a80000 {
				compatible = "qcom,geni-i2c";
				reg = <0x0 0x4a80000 0x0 0x4000>;

				interrupts = <GIC_SPI 527 IRQ_TYPE_LEVEL_HIGH>;

				clocks = <&gcc GCC_QUPV3_WRAP0_S0_CLK>;
				clock-names = "se";

				interconnects = <&clk_virt MASTER_QUP_CORE_0 RPM_ALWAYS_TAG
						 &clk_virt SLAVE_QUP_CORE_0 RPM_ALWAYS_TAG>,
						<&mem_noc MASTER_AMPSS_M0 RPM_ALWAYS_TAG
						 &config_noc SLAVE_QUP_0 RPM_ALWAYS_TAG>,
						<&system_noc MASTER_QUP_0 RPM_ALWAYS_TAG
						 &mc_virt SLAVE_EBI_CH0 RPM_ALWAYS_TAG>;
				interconnect-names = "qup-core",
						     "qup-config",
						     "qup-memory";

				dmas = <&gpi_dma0 0 0 QCOM_GPI_I2C>,
				       <&gpi_dma0 1 0 QCOM_GPI_I2C>;
				dma-names = "tx", "rx";

				pinctrl-0 = <&qup_i2c0_data_clk>;
				pinctrl-names = "default";

				#address-cells = <1>;
				#size-cells = <0>;

				status = "disabled";
			};

			spi0: spi@4a80000 {
				compatible = "qcom,geni-spi";
				reg = <0x0 0x4a80000 0x0 0x4000>;

				interrupts = <GIC_SPI 527 IRQ_TYPE_LEVEL_HIGH>;

				clocks = <&gcc GCC_QUPV3_WRAP0_S0_CLK>;
				clock-names = "se";

				interconnects = <&clk_virt MASTER_QUP_CORE_0 RPM_ALWAYS_TAG
						 &clk_virt SLAVE_QUP_CORE_0 RPM_ALWAYS_TAG>,
						<&mem_noc MASTER_AMPSS_M0 RPM_ALWAYS_TAG
						 &config_noc SLAVE_QUP_0 RPM_ALWAYS_TAG>;
				interconnect-names = "qup-core",
						     "qup-config";

				dmas = <&gpi_dma0 0 0 QCOM_GPI_SPI>,
				       <&gpi_dma0 1 0 QCOM_GPI_SPI>;
				dma-names = "tx", "rx";

				pinctrl-0 = <&qup_spi0_data_clk>, <&qup_spi0_cs>;
				pinctrl-names = "default";

				#address-cells = <1>;
				#size-cells = <0>;

				status = "disabled";
			};

			uart0: serial@4a80000 {
				compatible = "qcom,geni-debug-uart";
				reg = <0x0 0x04a80000 0x0 0x4000>;

				interrupts = <GIC_SPI 527 IRQ_TYPE_LEVEL_HIGH>;

				clocks = <&gcc GCC_QUPV3_WRAP0_S0_CLK>;
				clock-names = "se";

				interconnects = <&clk_virt MASTER_QUP_CORE_0 RPM_ALWAYS_TAG
						 &clk_virt SLAVE_QUP_CORE_0 RPM_ALWAYS_TAG>,
						<&mem_noc MASTER_AMPSS_M0 RPM_ALWAYS_TAG
						 &config_noc SLAVE_QUP_0 RPM_ALWAYS_TAG>;
				interconnect-names = "qup-core",
						     "qup-config";

				pinctrl-0 = <&qup_uart0_default>;
				pinctrl-names = "default";

				status = "disabled";
			};

			i2c1: i2c@4a84000 {
				compatible = "qcom,geni-i2c";
				reg = <0x0 0x4a84000 0x0 0x4000>;

				interrupts = <GIC_SPI 528 IRQ_TYPE_LEVEL_HIGH>;

				clocks = <&gcc GCC_QUPV3_WRAP0_S1_CLK>;
				clock-names = "se";

				interconnects = <&clk_virt MASTER_QUP_CORE_0 RPM_ALWAYS_TAG
						 &clk_virt SLAVE_QUP_CORE_0 RPM_ALWAYS_TAG>,
						<&mem_noc MASTER_AMPSS_M0 RPM_ALWAYS_TAG
						 &config_noc SLAVE_QUP_0 RPM_ALWAYS_TAG>,
						<&system_noc MASTER_QUP_0 RPM_ALWAYS_TAG
						 &mc_virt SLAVE_EBI_CH0 RPM_ALWAYS_TAG>;
				interconnect-names = "qup-core",
						     "qup-config",
						     "qup-memory";

				dmas = <&gpi_dma0 0 1 QCOM_GPI_I2C>,
				       <&gpi_dma0 1 1 QCOM_GPI_I2C>;
				dma-names = "tx", "rx";

				pinctrl-0 = <&qup_i2c1_data_clk>;
				pinctrl-names = "default";

				#address-cells = <1>;
				#size-cells = <0>;

				status = "disabled";
			};

			uart1: serial@4a84000 {
				compatible = "qcom,geni-uart";
				reg = <0x0 0x04a84000 0x0 0x4000>;

				interrupts = <GIC_SPI 528 IRQ_TYPE_LEVEL_HIGH>;

				clocks = <&gcc GCC_QUPV3_WRAP0_S1_CLK>;
				clock-names = "se";

				interconnects = <&clk_virt MASTER_QUP_CORE_0 RPM_ALWAYS_TAG
						 &clk_virt SLAVE_QUP_CORE_0 RPM_ALWAYS_TAG>,
						<&mem_noc MASTER_AMPSS_M0 RPM_ALWAYS_TAG
						 &config_noc SLAVE_QUP_0 RPM_ALWAYS_TAG>;
				interconnect-names = "qup-core",
						     "qup-config";

				pinctrl-0 = <&qup_uart1_default>;
				pinctrl-names = "default";

				status = "disabled";
			};

			i2c2: i2c@4a88000 {
				compatible = "qcom,geni-i2c";
				reg = <0x0 0x4a88000 0x0 0x4000>;

				interrupts = <GIC_SPI 529 IRQ_TYPE_LEVEL_HIGH>;

				clocks = <&gcc GCC_QUPV3_WRAP0_S2_CLK>;
				clock-names = "se";

				interconnects = <&clk_virt MASTER_QUP_CORE_0 RPM_ALWAYS_TAG
						 &clk_virt SLAVE_QUP_CORE_0 RPM_ALWAYS_TAG>,
						<&mem_noc MASTER_AMPSS_M0 RPM_ALWAYS_TAG
						 &config_noc SLAVE_QUP_0 RPM_ALWAYS_TAG>,
						<&system_noc MASTER_QUP_0 RPM_ALWAYS_TAG
						 &mc_virt SLAVE_EBI_CH0 RPM_ALWAYS_TAG>;
				interconnect-names = "qup-core",
						     "qup-config",
						     "qup-memory";

				pinctrl-0 = <&qup_i2c2_data_clk>;
				pinctrl-names = "default";

				dmas = <&gpi_dma0 0 2 QCOM_GPI_I2C>,
				       <&gpi_dma0 1 2 QCOM_GPI_I2C>;
				dma-names = "tx", "rx";

				#address-cells = <1>;
				#size-cells = <0>;

				status = "disabled";
			};

			spi2: spi@4a88000 {
				compatible = "qcom,geni-spi";
				reg = <0x0 0x4a88000 0x0 0x4000>;

				interrupts = <GIC_SPI 529 IRQ_TYPE_LEVEL_HIGH>;

				clocks = <&gcc GCC_QUPV3_WRAP0_S2_CLK>;
				clock-names = "se";

				interconnects = <&clk_virt MASTER_QUP_CORE_0 RPM_ALWAYS_TAG
						 &clk_virt SLAVE_QUP_CORE_0 RPM_ALWAYS_TAG>,
						<&mem_noc MASTER_AMPSS_M0 RPM_ALWAYS_TAG
						 &config_noc SLAVE_QUP_0 RPM_ALWAYS_TAG>;
				interconnect-names = "qup-core",
						     "qup-config";

				dmas = <&gpi_dma0 0 2 QCOM_GPI_SPI>,
				       <&gpi_dma0 1 2 QCOM_GPI_SPI>;
				dma-names = "tx", "rx";

				pinctrl-0 = <&qup_spi2_data_clk>, <&qup_spi2_cs>;
				pinctrl-names = "default";

				#address-cells = <1>;
				#size-cells = <0>;

				status = "disabled";
			};

			uart2: serial@4a88000 {
				compatible = "qcom,geni-uart";
				reg = <0x0 0x04a88000 0x0 0x4000>;

				interrupts-extended = <&intc GIC_SPI 529 IRQ_TYPE_LEVEL_HIGH>,
						      <&tlmm 9 IRQ_TYPE_LEVEL_HIGH>;

				clocks = <&gcc GCC_QUPV3_WRAP0_S2_CLK>;
				clock-names = "se";

				interconnects = <&clk_virt MASTER_QUP_CORE_0 RPM_ALWAYS_TAG
						 &clk_virt SLAVE_QUP_CORE_0 RPM_ALWAYS_TAG>,
						<&mem_noc MASTER_AMPSS_M0 RPM_ALWAYS_TAG
						 &config_noc SLAVE_QUP_0 RPM_ALWAYS_TAG>;
				interconnect-names = "qup-core",
						     "qup-config";

				pinctrl-0 = <&qup_uart2_default>, <&qup_uart2_cts_rts>;
				pinctrl-names = "default";

				status = "disabled";
			};

			i2c3: i2c@4a8c000 {
				compatible = "qcom,geni-i2c";
				reg = <0x0 0x4a8c000 0x0 0x4000>;

				interrupts = <GIC_SPI 530 IRQ_TYPE_LEVEL_HIGH>;

				clocks = <&gcc GCC_QUPV3_WRAP0_S3_CLK>;
				clock-names = "se";

				interconnects = <&clk_virt MASTER_QUP_CORE_0 RPM_ALWAYS_TAG
						 &clk_virt SLAVE_QUP_CORE_0 RPM_ALWAYS_TAG>,
						<&mem_noc MASTER_AMPSS_M0 RPM_ALWAYS_TAG
						 &config_noc SLAVE_QUP_0 RPM_ALWAYS_TAG>,
						<&system_noc MASTER_QUP_0 RPM_ALWAYS_TAG
						 &mc_virt SLAVE_EBI_CH0 RPM_ALWAYS_TAG>;
				interconnect-names = "qup-core",
						     "qup-config",
						     "qup-memory";

				dmas = <&gpi_dma0 0 3 QCOM_GPI_I2C>,
				       <&gpi_dma0 1 3 QCOM_GPI_I2C>;
				dma-names = "tx", "rx";

				pinctrl-0 = <&qup_i2c3_data_clk>;
				pinctrl-names = "default";

				#address-cells = <1>;
				#size-cells = <0>;

				status = "disabled";
			};

			uart3: serial@4a8c000 {
				compatible = "qcom,geni-uart";
				reg = <0x0 0x04a8c000 0x0 0x4000>;

				interrupts = <GIC_SPI 530 IRQ_TYPE_LEVEL_HIGH>;

				clocks = <&gcc GCC_QUPV3_WRAP0_S3_CLK>;
				clock-names = "se";

				interconnects = <&clk_virt MASTER_QUP_CORE_0 RPM_ALWAYS_TAG
						 &clk_virt SLAVE_QUP_CORE_0 RPM_ALWAYS_TAG>,
						<&mem_noc MASTER_AMPSS_M0 RPM_ALWAYS_TAG
						 &config_noc SLAVE_QUP_0 RPM_ALWAYS_TAG>;
				interconnect-names = "qup-core",
						     "qup-config";

				pinctrl-0 = <&qup_uart3_default>;
				pinctrl-names = "default";

				status = "disabled";
			};

			i2c4: i2c@4a90000 {
				compatible = "qcom,geni-i2c";
				reg = <0x0 0x4a90000 0x0 0x4000>;

				interrupts = <GIC_SPI 531 IRQ_TYPE_LEVEL_HIGH>;

				clocks = <&gcc GCC_QUPV3_WRAP0_S4_CLK>;
				clock-names = "se";

				interconnects = <&clk_virt MASTER_QUP_CORE_0 RPM_ALWAYS_TAG
						 &clk_virt SLAVE_QUP_CORE_0 RPM_ALWAYS_TAG>,
						<&mem_noc MASTER_AMPSS_M0 RPM_ALWAYS_TAG
						 &config_noc SLAVE_QUP_0 RPM_ALWAYS_TAG>,
						<&system_noc MASTER_QUP_0 RPM_ALWAYS_TAG
						 &mc_virt SLAVE_EBI_CH0 RPM_ALWAYS_TAG>;
				interconnect-names = "qup-core",
						     "qup-config",
						     "qup-memory";

				dmas = <&gpi_dma0 0 4 QCOM_GPI_I2C>,
				       <&gpi_dma0 1 4 QCOM_GPI_I2C>;
				dma-names = "tx", "rx";

				pinctrl-0 = <&qup_i2c4_data_clk>;
				pinctrl-names = "default";

				#address-cells = <1>;
				#size-cells = <0>;

				status = "disabled";
			};

			uart4: serial@4a90000 {
				compatible = "qcom,geni-uart";
				reg = <0x0 0x04a90000 0x0 0x4000>;

				interrupts = <GIC_SPI 531 IRQ_TYPE_LEVEL_HIGH>;

				clocks = <&gcc GCC_QUPV3_WRAP0_S4_CLK>;
				clock-names = "se";

				interconnects = <&clk_virt MASTER_QUP_CORE_0 RPM_ALWAYS_TAG
						 &clk_virt SLAVE_QUP_CORE_0 RPM_ALWAYS_TAG>,
						<&mem_noc MASTER_AMPSS_M0 RPM_ALWAYS_TAG
						 &config_noc SLAVE_QUP_0 RPM_ALWAYS_TAG>;
				interconnect-names = "qup-core",
						     "qup-config";

				pinctrl-0 = <&qup_uart4_default>;
				pinctrl-names = "default";

				status = "disabled";
			};

			i2c5: i2c@4a94000 {
				compatible = "qcom,geni-i2c";
				reg = <0x0 0x4a94000 0x0 0x4000>;

				interrupts = <GIC_SPI 532 IRQ_TYPE_LEVEL_HIGH>;

				clocks = <&gcc GCC_QUPV3_WRAP0_S5_CLK>;
				clock-names = "se";

				interconnects = <&clk_virt MASTER_QUP_CORE_0 RPM_ALWAYS_TAG
						 &clk_virt SLAVE_QUP_CORE_0 RPM_ALWAYS_TAG>,
						<&mem_noc MASTER_AMPSS_M0 RPM_ALWAYS_TAG
						 &config_noc SLAVE_QUP_0 RPM_ALWAYS_TAG>,
						<&system_noc MASTER_QUP_0 RPM_ALWAYS_TAG
						 &mc_virt SLAVE_EBI_CH0 RPM_ALWAYS_TAG>;
				interconnect-names = "qup-core",
						     "qup-config",
						     "qup-memory";

				dmas = <&gpi_dma0 0 5 QCOM_GPI_I2C>,
				       <&gpi_dma0 1 5 QCOM_GPI_I2C>;
				dma-names = "tx", "rx";

				pinctrl-0 = <&qup_i2c5_data_clk>;
				pinctrl-names = "default";

				#address-cells = <1>;
				#size-cells = <0>;

				status = "disabled";
			};

			spi5: spi@4a94000 {
				compatible = "qcom,geni-spi";
				reg = <0x0 0x4a94000 0x0 0x4000>;

				interrupts = <GIC_SPI 532 IRQ_TYPE_LEVEL_HIGH>;

				clocks = <&gcc GCC_QUPV3_WRAP0_S5_CLK>;
				clock-names = "se";

				interconnects = <&clk_virt MASTER_QUP_CORE_0 RPM_ALWAYS_TAG
						 &clk_virt SLAVE_QUP_CORE_0 RPM_ALWAYS_TAG>,
						<&mem_noc MASTER_AMPSS_M0 RPM_ALWAYS_TAG
						 &config_noc SLAVE_QUP_0 RPM_ALWAYS_TAG>;
				interconnect-names = "qup-core",
						     "qup-config";

				dmas = <&gpi_dma0 0 5 QCOM_GPI_SPI>,
				       <&gpi_dma0 1 5 QCOM_GPI_SPI>;
				dma-names = "tx", "rx";

				pinctrl-0 = <&qup_spi5_data_clk>, <&qup_spi5_cs>;
				pinctrl-names = "default";

				#address-cells = <1>;
				#size-cells = <0>;

				status = "disabled";
			};

			uart5: serial@4a94000 {
				compatible = "qcom,geni-uart";
				reg = <0x0 0x04a94000 0x0 0x4000>;

				interrupts = <GIC_SPI 532 IRQ_TYPE_LEVEL_HIGH>;

				clocks = <&gcc GCC_QUPV3_WRAP0_S5_CLK>;
				clock-names = "se";

				interconnects = <&clk_virt MASTER_QUP_CORE_0 RPM_ALWAYS_TAG
						 &clk_virt SLAVE_QUP_CORE_0 RPM_ALWAYS_TAG>,
						<&mem_noc MASTER_AMPSS_M0 RPM_ALWAYS_TAG
						 &config_noc SLAVE_QUP_0 RPM_ALWAYS_TAG>;
				interconnect-names = "qup-core",
						     "qup-config";

				pinctrl-0 = <&qup_uart5_default>, <&qup_uart5_cts_rts>;
				pinctrl-names = "default";

				status = "disabled";
			};

			i2c6: i2c@4a98000 {
				compatible = "qcom,geni-i2c";
				reg = <0x0 0x4a98000 0x0 0x4000>;

				interrupts = <GIC_SPI 533 IRQ_TYPE_LEVEL_HIGH>;

				clocks = <&gcc GCC_QUPV3_WRAP0_S6_CLK>;
				clock-names = "se";

				interconnects = <&clk_virt MASTER_QUP_CORE_0 RPM_ALWAYS_TAG
						 &clk_virt SLAVE_QUP_CORE_0 RPM_ALWAYS_TAG>,
						<&mem_noc MASTER_AMPSS_M0 RPM_ALWAYS_TAG
						 &config_noc SLAVE_QUP_0 RPM_ALWAYS_TAG>,
						<&system_noc MASTER_QUP_0 RPM_ALWAYS_TAG
						 &mc_virt SLAVE_EBI_CH0 RPM_ALWAYS_TAG>;
				interconnect-names = "qup-core",
						     "qup-config",
						     "qup-memory";

				dmas = <&gpi_dma0 0 6 QCOM_GPI_I2C>,
				       <&gpi_dma0 1 6 QCOM_GPI_I2C>;
				dma-names = "tx", "rx";

				pinctrl-0 = <&qup_i2c6_data_clk>;
				pinctrl-names = "default";

				#address-cells = <1>;
				#size-cells = <0>;

				status = "disabled";
			};

			spi6: spi@4a98000 {
				compatible = "qcom,geni-spi";
				reg = <0x0 0x4a98000 0x0 0x4000>;

				interrupts = <GIC_SPI 533 IRQ_TYPE_LEVEL_HIGH>;

				clocks = <&gcc GCC_QUPV3_WRAP0_S6_CLK>;
				clock-names = "se";

				interconnects =	<&clk_virt MASTER_QUP_CORE_0 RPM_ALWAYS_TAG
						 &clk_virt SLAVE_QUP_CORE_0 RPM_ALWAYS_TAG>,
						<&mem_noc MASTER_AMPSS_M0 RPM_ALWAYS_TAG
						 &config_noc SLAVE_QUP_0 RPM_ALWAYS_TAG>;
				interconnect-names = "qup-core",
						     "qup-config";

				dmas = <&gpi_dma0 0 6 QCOM_GPI_SPI>,
				       <&gpi_dma0 1 6 QCOM_GPI_SPI>;
				dma-names = "tx", "rx";

				pinctrl-0 = <&qup_spi6_data_clk>, <&qup_spi6_cs>;
				pinctrl-names = "default";

				#address-cells = <1>;
				#size-cells = <0>;

				status = "disabled";
			};

			uart6: serial@4a98000 {
				compatible = "qcom,geni-uart";
				reg = <0x0 0x04a98000 0x0 0x4000>;

				interrupts = <GIC_SPI 533 IRQ_TYPE_LEVEL_HIGH>;

				clocks = <&gcc GCC_QUPV3_WRAP0_S6_CLK>;
				clock-names = "se";

				interconnects = <&clk_virt MASTER_QUP_CORE_0 RPM_ALWAYS_TAG
						 &clk_virt SLAVE_QUP_CORE_0 RPM_ALWAYS_TAG>,
						<&mem_noc MASTER_AMPSS_M0 RPM_ALWAYS_TAG
						 &config_noc SLAVE_QUP_0 RPM_ALWAYS_TAG>;
				interconnect-names = "qup-core",
						     "qup-config";

				pinctrl-0 = <&qup_uart6_default>, <&qup_uart6_cts_rts>;
				pinctrl-names = "default";

				status = "disabled";
			};

			i2c7: i2c@4a9c000 {
				compatible = "qcom,geni-i2c";
				reg = <0x0 0x4a9c000 0x0 0x4000>;

				interrupts = <GIC_SPI 534 IRQ_TYPE_LEVEL_HIGH>;

				clocks = <&gcc GCC_QUPV3_WRAP0_S7_CLK>;
				clock-names = "se";

				interconnects = <&clk_virt MASTER_QUP_CORE_0 RPM_ALWAYS_TAG
						 &clk_virt SLAVE_QUP_CORE_0 RPM_ALWAYS_TAG>,
						<&mem_noc MASTER_AMPSS_M0 RPM_ALWAYS_TAG
						 &config_noc SLAVE_QUP_0 RPM_ALWAYS_TAG>,
						<&system_noc MASTER_QUP_0 RPM_ALWAYS_TAG
						 &mc_virt SLAVE_EBI_CH0 RPM_ALWAYS_TAG>;
				interconnect-names = "qup-core",
						     "qup-config",
						     "qup-memory";

				dmas = <&gpi_dma0 0 7 QCOM_GPI_I2C>,
				       <&gpi_dma0 1 7 QCOM_GPI_I2C>;
				dma-names = "tx", "rx";

				pinctrl-0 = <&qup_i2c7_data_clk>;
				pinctrl-names = "default";

				#address-cells = <1>;
				#size-cells = <0>;

				status = "disabled";
			};

			uart7: serial@4a9c000 {
				compatible = "qcom,geni-uart";
				reg = <0x0 0x04a9c000 0x0 0x4000>;

				interrupts = <GIC_SPI 534 IRQ_TYPE_LEVEL_HIGH>;

				clocks = <&gcc GCC_QUPV3_WRAP0_S7_CLK>;
				clock-names = "se";

				interconnects = <&clk_virt MASTER_QUP_CORE_0 RPM_ALWAYS_TAG
						 &clk_virt SLAVE_QUP_CORE_0 RPM_ALWAYS_TAG>,
						<&mem_noc MASTER_AMPSS_M0 RPM_ALWAYS_TAG
						 &config_noc SLAVE_QUP_0 RPM_ALWAYS_TAG>;
				interconnect-names = "qup-core",
						     "qup-config";

				pinctrl-0 = <&qup_uart7_default>;
				pinctrl-names = "default";

				status = "disabled";
			};

			i2c8: i2c@4aa0000 {
				compatible = "qcom,geni-i2c";
				reg = <0x0 0x4aa0000 0x0 0x4000>;

				interrupts = <GIC_SPI 535 IRQ_TYPE_LEVEL_HIGH>;

				clocks = <&gcc GCC_QUPV3_WRAP0_S8_CLK>;
				clock-names = "se";

				interconnects = <&clk_virt MASTER_QUP_CORE_0 RPM_ALWAYS_TAG
						 &clk_virt SLAVE_QUP_CORE_0 RPM_ALWAYS_TAG>,
						<&mem_noc MASTER_AMPSS_M0 RPM_ALWAYS_TAG
						 &config_noc SLAVE_QUP_0 RPM_ALWAYS_TAG>,
						<&system_noc MASTER_QUP_0 RPM_ALWAYS_TAG
						 &mc_virt SLAVE_EBI_CH0 RPM_ALWAYS_TAG>;
				interconnect-names = "qup-core",
						     "qup-config",
						     "qup-memory";

				dmas = <&gpi_dma0 0 8 QCOM_GPI_I2C>,
				       <&gpi_dma0 1 8 QCOM_GPI_I2C>;
				dma-names = "tx", "rx";

				pinctrl-0 = <&qup_i2c8_data_clk>;
				pinctrl-names = "default";

				#address-cells = <1>;
				#size-cells = <0>;

				status = "disabled";
			};

			spi8: spi@4aa0000 {
				compatible = "qcom,geni-spi";
				reg = <0x0 0x4aa0000 0x0 0x4000>;

				interrupts = <GIC_SPI 535 IRQ_TYPE_LEVEL_HIGH>;

				clocks = <&gcc GCC_QUPV3_WRAP0_S8_CLK>;
				clock-names = "se";

				interconnects =	<&clk_virt MASTER_QUP_CORE_0 RPM_ALWAYS_TAG
						 &clk_virt SLAVE_QUP_CORE_0 RPM_ALWAYS_TAG>,
						<&mem_noc MASTER_AMPSS_M0 RPM_ALWAYS_TAG
						 &config_noc SLAVE_QUP_0 RPM_ALWAYS_TAG>;
				interconnect-names = "qup-core",
						     "qup-config";

				dmas = <&gpi_dma0 0 8 QCOM_GPI_SPI>,
				       <&gpi_dma0 1 8 QCOM_GPI_SPI>;
				dma-names = "tx", "rx";

				pinctrl-0 = <&qup_spi8_data_clk>, <&qup_spi8_cs>;
				pinctrl-names = "default";

				#address-cells = <1>;
				#size-cells = <0>;

				status = "disabled";
			};

			uart8: serial@4aa0000 {
				compatible = "qcom,geni-uart";
				reg = <0x0 0x04aa0000 0x0 0x4000>;

				interrupts = <GIC_SPI 535 IRQ_TYPE_LEVEL_HIGH>;

				clocks = <&gcc GCC_QUPV3_WRAP0_S8_CLK>;
				clock-names = "se";

				interconnects = <&clk_virt MASTER_QUP_CORE_0 RPM_ALWAYS_TAG
						 &clk_virt SLAVE_QUP_CORE_0 RPM_ALWAYS_TAG>,
						<&mem_noc MASTER_AMPSS_M0 RPM_ALWAYS_TAG
						 &config_noc SLAVE_QUP_0 RPM_ALWAYS_TAG>;
				interconnect-names = "qup-core",
						     "qup-config";

				pinctrl-0 = <&qup_uart8_default>, <&qup_uart8_cts_rts>;
				pinctrl-names = "default";

				status = "disabled";

				bluetooth {
					compatible = "qcom,wcn3988-bt";

					enable-gpios = <&tlmm 88 GPIO_ACTIVE_HIGH>;
					max-speed = <3200000>;
				};

			};

			i2c9: i2c@4aa4000 {
				compatible = "qcom,geni-i2c";
				reg = <0x0 0x4aa4000 0x0 0x4000>;

				interrupts = <GIC_SPI 536 IRQ_TYPE_LEVEL_HIGH>;

				clocks = <&gcc GCC_QUPV3_WRAP0_S9_CLK>;
				clock-names = "se";

				interconnects = <&clk_virt MASTER_QUP_CORE_0 RPM_ALWAYS_TAG
						 &clk_virt SLAVE_QUP_CORE_0 RPM_ALWAYS_TAG>,
						<&mem_noc MASTER_AMPSS_M0 RPM_ALWAYS_TAG
						 &config_noc SLAVE_QUP_0 RPM_ALWAYS_TAG>,
						<&system_noc MASTER_QUP_0 RPM_ALWAYS_TAG
						 &mc_virt SLAVE_EBI_CH0 RPM_ALWAYS_TAG>;
				interconnect-names = "qup-core",
						     "qup-config",
						     "qup-memory";

				dmas = <&gpi_dma0 0 9 QCOM_GPI_I2C>,
				       <&gpi_dma0 1 9 QCOM_GPI_I2C>;
				dma-names = "tx", "rx";

				pinctrl-0 = <&qup_i2c9_data_clk>;
				pinctrl-names = "default";

				#address-cells = <1>;
				#size-cells = <0>;

				status = "disabled";
			};

			uart9: serial@4aa4000 {
				compatible = "qcom,geni-uart";
				reg = <0x0 0x04aa4000 0x0 0x4000>;

				interrupts = <GIC_SPI 536 IRQ_TYPE_LEVEL_HIGH>;

				clocks = <&gcc GCC_QUPV3_WRAP0_S9_CLK>;
				clock-names = "se";

				interconnects = <&clk_virt MASTER_QUP_CORE_0 RPM_ALWAYS_TAG
						 &clk_virt SLAVE_QUP_CORE_0 RPM_ALWAYS_TAG>,
						<&mem_noc MASTER_AMPSS_M0 RPM_ALWAYS_TAG
						 &config_noc SLAVE_QUP_0 RPM_ALWAYS_TAG>;
				interconnect-names = "qup-core",
						     "qup-config";

				pinctrl-0 = <&qup_uart9_default>;
				pinctrl-names = "default";

				status = "disabled";
			};
		};

		remoteproc_mpss: remoteproc@6080000 {
			compatible = "qcom,shikra-mpss-pas";
			reg = <0x0 0x06080000 0x0 0x100>;

			interrupts-extended = <&intc GIC_SPI 307 IRQ_TYPE_EDGE_RISING>,
					      <&modem_smp2p_in 0 IRQ_TYPE_EDGE_RISING>,
					      <&modem_smp2p_in 1 IRQ_TYPE_EDGE_RISING>,
					      <&modem_smp2p_in 2 IRQ_TYPE_EDGE_RISING>,
					      <&modem_smp2p_in 3 IRQ_TYPE_EDGE_RISING>,
					      <&modem_smp2p_in 7 IRQ_TYPE_EDGE_RISING>;
			interrupt-names = "wdog",
					  "fatal",
					  "ready",
					  "handover",
					  "stop-ack",
					  "shutdown-ack";

			clocks = <&rpmcc RPM_SMD_XO_CLK_SRC>;
			clock-names = "xo";

			interconnects = <&mem_noc MASTER_AMPSS_M0 RPM_ALWAYS_TAG
					 &mc_virt SLAVE_EBI_CH0 RPM_ALWAYS_TAG>,
					<&system_noc MASTER_CRYPTO_CORE0 RPM_ALWAYS_TAG
					 &mc_virt SLAVE_EBI_CH0 RPM_ALWAYS_TAG>;

			power-domains = <&rpmpd RPMHPD_CX>;

			memory-region = <&mpss_wlan_mem>;

			qcom,smem-states = <&modem_smp2p_out 0>;
			qcom,smem-state-names = "stop";

			status = "disabled";

			glink-edge {
				interrupts = <GIC_SPI 68 IRQ_TYPE_EDGE_RISING>;
				mboxes = <&apcs_glb 12>;
				qcom,remote-pid = <1>;
				label = "mpss";
			};
		};

		ctcu@8001000 {
			compatible = "qcom,shikra-ctcu","qcom,sa8775p-ctcu";
			reg = <0x0 0x08001000 0x0 0x1000>;

			clocks = <&rpmcc RPM_SMD_QDSS_CLK>;
			clock-names = "apb";

			in-ports {
				port {
					ctcu_in0: endpoint {
						remote-endpoint = <&etr0_out>;
					};
				};
			};
		};

		stm@8002000 {
			compatible = "arm,coresight-stm", "arm,primecell";
			reg = <0x0 0x08002000 0x0 0x1000>,
			      <0x0 0x0e280000 0x0 0x180000>;
			reg-names = "stm-base",
				    "stm-stimulus-base";

			clocks = <&rpmcc RPM_SMD_QDSS_CLK>;
			clock-names = "apb_pclk";

			out-ports {
				port {
					stm_out: endpoint {
						remote-endpoint = <&funnel_in0_in7>;
					};
				};
			};
		};

		tpdm@8003000 {
			compatible = "qcom,coresight-tpdm", "arm,primecell";
			reg = <0x0 0x08003000 0x0 0x1000>;

			clocks = <&rpmcc RPM_SMD_QDSS_CLK>;
			clock-names = "apb_pclk";

			label = "tpdm_dcc";
			qcom,cmb-element-bits = <32>;

			out-ports {
				port {
					tpdm_dcc_out: endpoint {
						remote-endpoint = <&tpda_qdss_in0>;
					};
				};
			};
		};

		tpda@8004000 {
			compatible = "qcom,coresight-tpda", "arm,primecell";
			reg = <0x0 0x08004000 0x0 0x1000>;

			clocks = <&rpmcc RPM_SMD_QDSS_CLK>;
			clock-names = "apb_pclk";

			in-ports {
				#address-cells = <1>;
				#size-cells = <0>;

				port@0 {
					reg = <0>;

					tpda_qdss_in0: endpoint {
						remote-endpoint = <&tpdm_dcc_out>;
					};
				};

				port@1 {
					reg = <1>;

					tpda_qdss_in1: endpoint {
						remote-endpoint = <&tpdm_spdm_out>;
					};
				};
			};

			out-ports {
				port {
					tpda_qdss_out: endpoint {
						remote-endpoint = <&funnel_in0_in6>;
					};
				};
			};
		};

		tpdm@800f000 {
			compatible = "qcom,coresight-tpdm", "arm,primecell";
			reg = <0x0 0x0800f000 0x0 0x1000>;

			clocks = <&rpmcc RPM_SMD_QDSS_CLK>;
			clock-names = "apb_pclk";

			label = "tpdm_spdm";
			qcom,cmb-element-bits = <32>;

			out-ports {
				port {
					tpdm_spdm_out: endpoint {
						remote-endpoint = <&tpda_qdss_in1>;
					};
				};
			};
		};

		funnel@8041000 {
			compatible = "arm,coresight-dynamic-funnel", "arm,primecell";
			reg = <0x0 0x08041000 0x0 0x1000>;

			clocks = <&rpmcc RPM_SMD_QDSS_CLK>;
			clock-names = "apb_pclk";

			in-ports {
				#address-cells = <1>;
				#size-cells = <0>;

				port@5 {
					reg = <5>;

					funnel_in0_in5: endpoint {
						remote-endpoint = <&snoc_out>;
					};
				};

				port@6 {
					reg = <6>;

					funnel_in0_in6: endpoint {
						remote-endpoint = <&tpda_qdss_out>;
					};
				};

				port@7 {
					reg = <7>;

					funnel_in0_in7: endpoint {
						remote-endpoint = <&stm_out>;
					};
				};
			};

			out-ports {
				port {
					funnel_in0_out: endpoint {
						remote-endpoint = <&funnel_merg_in0>;
					};
				};
			};
		};

		funnel@8042000 {
			compatible = "arm,coresight-dynamic-funnel", "arm,primecell";
			reg = <0x0 0x08042000 0x0 0x1000>;

			clocks = <&rpmcc RPM_SMD_QDSS_CLK>;
			clock-names = "apb_pclk";

			in-ports {
				#address-cells = <1>;
				#size-cells = <0>;

				port@1 {
					reg = <1>;

					funnel_in1_in1: endpoint {
						remote-endpoint = <&tpda_aodbg_out>;
					};
				};

				port@4 {
					reg = <4>;

					funnel_in1_in4: endpoint {
						remote-endpoint = <&modem_etm0_out>;
					};
				};

				port@6 {
					reg = <6>;

					funnel_in1_in6: endpoint {
						remote-endpoint = <&funnel_cpuss1_out>;
					};
				};

				port@7 {
					reg = <7>;

					funnel_in1_in7: endpoint {
						remote-endpoint = <&funnel_center_out>;
					};
				};
			};

			out-ports {
				port {
					funnel_in1_out: endpoint {
						remote-endpoint = <&funnel_merg_in1>;
					};
				};
			};
		};

		funnel@8045000 {
			compatible = "arm,coresight-dynamic-funnel", "arm,primecell";
			reg = <0x0 0x08045000 0x0 0x1000>;

			clocks = <&rpmcc RPM_SMD_QDSS_CLK>;
			clock-names = "apb_pclk";

			in-ports {
				#address-cells = <1>;
				#size-cells = <0>;

				port@0 {
					reg = <0>;

					funnel_merg_in0: endpoint {
						remote-endpoint = <&funnel_in0_out>;
					};
				};

				port@1 {
					reg = <1>;

					funnel_merg_in1: endpoint {
						remote-endpoint = <&funnel_in1_out>;
					};
				};
			};

			out-ports {
				port {
					funnel_merg_out: endpoint {
						remote-endpoint = <&tmc_etf_in>;
					};
				};
			};
		};

		replicator@8046000 {
			compatible = "arm,coresight-dynamic-replicator", "arm,primecell";
			reg = <0x0 0x08046000 0x0 0x1000>;

			clocks = <&rpmcc RPM_SMD_QDSS_CLK>;
			clock-names = "apb_pclk";

			in-ports {
				port {
					replicator_qdss_in: endpoint {
						remote-endpoint = <&tmc_etf_out>;
					};
				};
			};

			out-ports {
				#address-cells = <1>;
				#size-cells = <0>;

				port@0 {
					reg = <0>;

					replicator_qdss_out0: endpoint {
						remote-endpoint = <&etr0_in>;
					};
				};

				port@1 {
					reg = <1>;

					replicator_qdss_out1: endpoint {
						remote-endpoint = <&replicator_eud_in>;
					};
				};
			};
		};

		tmc@8047000 {
			compatible = "arm,coresight-tmc", "arm,primecell";
			reg = <0x0 0x08047000 0x0 0x1000>;

			clocks = <&rpmcc RPM_SMD_QDSS_CLK>;
			clock-names = "apb_pclk";

			in-ports {
				port {
					tmc_etf_in: endpoint {
						remote-endpoint = <&funnel_merg_out>;
					};
				};
			};

			out-ports {
				port {
					tmc_etf_out: endpoint {
						remote-endpoint = <&replicator_qdss_in>;
					};
				};
			};
		};

		tmc@8048000 {
			compatible = "arm,coresight-tmc", "arm,primecell";
			reg = <0x0 0x08048000 0x0 0x1000>;

			clocks = <&rpmcc RPM_SMD_QDSS_CLK>;
			clock-names = "apb_pclk";

			iommus = <&apps_smmu 0x0160 0x0>;
			arm,scatter-gather;

			in-ports {
				port {
					etr0_in: endpoint {
						remote-endpoint = <&replicator_qdss_out0>;
					};
				};
			};

			out-ports {
				port {
					etr0_out: endpoint {
						remote-endpoint = <&ctcu_in0>;
					};
				};
			};
		};

		replicator@804a000 {
			compatible = "arm,coresight-dynamic-replicator", "arm,primecell";
			reg = <0x0 0x0804a000 0x0 0x1000>;

			clocks = <&rpmcc RPM_SMD_QDSS_CLK>;
			clock-names = "apb_pclk";

			in-ports {
				port {
					replicator_eud_in: endpoint {
						remote-endpoint = <&replicator_qdss_out1>;
					};
				};
			};

			out-ports {
				#address-cells = <1>;
				#size-cells = <0>;

				port@1 {
					reg = <1>;

					replicator_eud_out1: endpoint {
						remote-endpoint = <&eud_in>;
					};
				};
			};
		};

		tpdm@8800000 {
			compatible = "qcom,coresight-tpdm", "arm,primecell";
			reg = <0x0 0x08800000 0x0 0x1000>;

			clocks = <&rpmcc RPM_SMD_QDSS_CLK>;
			clock-names = "apb_pclk";

			label = "tpdm_cdsp";
			qcom,dsb-element-bits = <32>;
			qcom,dsb-msrs-num = <4>;

			out-ports {
				port {
					tpdm_cdsp_out: endpoint {
						remote-endpoint = <&funnel_cdsp_in0>;
					};
				};
			};
		};

		funnel@8801000 {
			compatible = "arm,coresight-dynamic-funnel", "arm,primecell";
			reg = <0x0 0x08801000 0x0 0x1000>;

			clocks = <&rpmcc RPM_SMD_QDSS_CLK>;
			clock-names = "apb_pclk";

			in-ports {
				port {
					funnel_cdsp_in0: endpoint {
						remote-endpoint = <&tpdm_cdsp_out>;
					};
				};
			};

			out-ports {
				port {
					funnel_cdsp_out0: endpoint {
						remote-endpoint = <&tpda_center_in3>;
					};
				};
			};
		};

		cti@8807000 {
			compatible = "arm,coresight-cti", "arm,primecell";
			reg = <0x0 0x08807000 0x0 0x1000>;

			clocks = <&rpmcc RPM_SMD_QDSS_CLK>;
			clock-names = "apb_pclk";
			label = "cti_turing_q6";
		};

		cti@8833000 {
			compatible = "arm,coresight-cti", "arm,primecell";
			reg = <0x0 0x08833000 0x0 0x1000>;

			clocks = <&rpmcc RPM_SMD_QDSS_CLK>;
			clock-names = "apb_pclk";
			label = "cti_mss_q6";
		};

		tpdm@8840000 {
			compatible = "qcom,coresight-tpdm", "arm,primecell";
			reg = <0x0 0x08840000 0x0 0x1000>;

			clocks = <&rpmcc RPM_SMD_QDSS_CLK>;
			clock-names = "apb_pclk";

			label = "tpdm_vsense";
			qcom,cmb-element-bits = <32>;

			out-ports {
				port {
					tpdm_vsense_out: endpoint {
						remote-endpoint = <&tpda_center_in6>;
					};
				};
			};
		};

		tpdm@8844000 {
			compatible = "qcom,coresight-tpdm", "arm,primecell";
			reg = <0x0 0x08844000 0x0 0x1000>;

			clocks = <&rpmcc RPM_SMD_QDSS_CLK>;
			clock-names = "apb_pclk";

			label = "tpdm_dlct_1";
			qcom,dsb-element-bits = <32>;
			qcom,dsb-msrs-num = <32>;

			out-ports {
				port {
					tpdm_dlct_1_out: endpoint {
						remote-endpoint = <&tpda_center_in13>;
					};
				};
			};
		};

		tpda@8845000 {
			compatible = "qcom,coresight-tpda", "arm,primecell";
			reg = <0x0 0x08845000 0x0 0x1000>;

			clocks = <&rpmcc RPM_SMD_QDSS_CLK>;
			clock-names = "apb_pclk";

			in-ports {
				#address-cells = <1>;
				#size-cells = <0>;

				port@0 {
					reg = <0>;

					tpda_center_in0: endpoint {
						remote-endpoint = <&funnel_mcu_out>;
					};
				};

				port@2 {
					reg = <2>;

					tpda_center_in2: endpoint {
						remote-endpoint = <&tpdm_dlct_out>;
					};
				};

				port@3 {
					reg = <3>;

					tpda_center_in3: endpoint {
						remote-endpoint = <&funnel_cdsp_out0>;
					};
				};

				port@4 {
					reg = <4>;

					tpda_center_in4: endpoint {
						remote-endpoint = <&funnel_ddr_out0>;
					};
				};

				port@6 {
					reg = <6>;

					tpda_center_in6: endpoint {
						remote-endpoint = <&tpdm_vsense_out>;
					};
				};

				port@7 {
					reg = <7>;

					tpda_center_in7: endpoint {
						remote-endpoint = <&tpdm_prng_out>;
					};
				};

				port@8 {
					reg = <8>;

					tpda_center_in8: endpoint {
						remote-endpoint = <&tpdm_west_out>;
					};
				};

				port@9 {
					reg = <9>;

					tpda_center_in9: endpoint {
						remote-endpoint = <&tpdm_qm_out>;
					};
				};

				port@a {
					reg = <0xa>;

					tpda_center_in10: endpoint {
						remote-endpoint = <&tpdm_pimem_out>;
					};
				};

				port@d {
					reg = <0xd>;

					tpda_center_in13: endpoint {
						remote-endpoint = <&tpdm_dlct_1_out>;
					};
				};
			};

			out-ports {
				port {
					tpda_center_out: endpoint {
						remote-endpoint = <&funnel_center_in0>;
					};
				};
			};
		};

		funnel@8846000 {
			compatible = "arm,coresight-dynamic-funnel", "arm,primecell";
			reg = <0x0 0x08846000 0x0 0x1000>;

			clocks = <&rpmcc RPM_SMD_QDSS_CLK>;
			clock-names = "apb_pclk";

			in-ports {
				port {
					funnel_center_in0: endpoint {
						remote-endpoint = <&tpda_center_out>;
					};
				};
			};

			out-ports {
				port {
					funnel_center_out: endpoint {
						remote-endpoint = <&funnel_in1_in7>;
					};
				};
			};
		};

		tpdm@884c000 {
			compatible = "qcom,coresight-tpdm", "arm,primecell";
			reg = <0x0 0x0884c000 0x0 0x1000>;

			clocks = <&rpmcc RPM_SMD_QDSS_CLK>;
			clock-names = "apb_pclk";

			label = "tpdm_prng";
			qcom,cmb-element-bits = <32>;

			out-ports {
				port {
					tpdm_prng_out: endpoint {
						remote-endpoint = <&tpda_center_in7>;
					};
				};
			};
		};

		tpdm@8850000 {
			compatible = "qcom,coresight-tpdm", "arm,primecell";
			reg = <0x0 0x08850000 0x0 0x1000>;

			clocks = <&rpmcc RPM_SMD_QDSS_CLK>;
			clock-names = "apb_pclk";

			label = "tpdm_pimem";
			qcom,cmb-element-bits = <64>;
			qcom,dsb-element-bits = <32>;

			out-ports {
				port {
					tpdm_pimem_out: endpoint {
						remote-endpoint = <&tpda_center_in10>;
					};
				};
			};
		};

		tpdm@8980000 {
			compatible = "qcom,coresight-tpdm", "arm,primecell";
			reg = <0x0 0x08980000 0x0 0x1000>;

			clocks = <&rpmcc RPM_SMD_QDSS_CLK>;
			clock-names = "apb_pclk";

			label = "tpdm_mcu";
			qcom,dsb-element-bits = <32>;
			qcom,dsb-msrs-num = <16>;

			out-ports {
				port {
					tpdm_mcu_out: endpoint {
						remote-endpoint = <&funnel_mcu_in0>;
					};
				};
			};
		};

		funnel@8982000 {
			compatible = "arm,coresight-dynamic-funnel", "arm,primecell";
			reg = <0x0 0x08982000 0x0 0x1000>;

			clocks = <&rpmcc RPM_SMD_QDSS_CLK>;
			clock-names = "apb_pclk";

			in-ports {
				port {
					funnel_mcu_in0: endpoint {
						remote-endpoint = <&tpdm_mcu_out>;
					};
				};
			};

			out-ports {
				port {
					funnel_mcu_out: endpoint {
						remote-endpoint = <&tpda_center_in0>;
					};
				};
			};
		};

		tpdm@89d0000 {
			compatible = "qcom,coresight-tpdm", "arm,primecell";
			reg = <0x0 0x089d0000 0x0 0x1000>;

			clocks = <&rpmcc RPM_SMD_QDSS_CLK>;
			clock-names = "apb_pclk";

			label = "tpdm_qm";
			qcom,dsb-element-bits = <32>;

			out-ports {
				port {
					tpdm_qm_out: endpoint {
						remote-endpoint = <&tpda_center_in9>;
					};
				};
			};
		};

		tpdm@8a01000 {
			compatible = "qcom,coresight-tpdm", "arm,primecell";
			reg = <0x0 0x08a01000 0x0 0x1000>;

			clocks = <&rpmcc RPM_SMD_QDSS_CLK>;
			clock-names = "apb_pclk";

			label = "tpdm_mapss";
			qcom,cmb-element-bits = <32>;
			qcom,dsb-element-bits = <32>;
			qcom,dsb-msrs-num = <16>;

			out-ports {
				port {
					tpdm_mapss_out: endpoint {
						remote-endpoint = <&tpda_aodbg_in>;
					};
				};
			};
		};

		cti@8a02000 {
			compatible = "arm,coresight-cti", "arm,primecell";
			reg = <0x0 0x08a02000 0x0 0x1000>;

			clocks = <&rpmcc RPM_SMD_QDSS_CLK>;
			clock-names = "apb_pclk";
			label = "cti_mapss";
		};

		tpda@8a04000 {
			compatible = "qcom,coresight-tpda", "arm,primecell";
			reg = <0x0 0x08a04000 0x0 0x1000>;

			clocks = <&rpmcc RPM_SMD_QDSS_CLK>;
			clock-names = "apb_pclk";

			in-ports {
				port {
					tpda_aodbg_in: endpoint {
						remote-endpoint = <&tpdm_mapss_out>;
					};
				};
			};

			out-ports {
				port {
					tpda_aodbg_out: endpoint {
						remote-endpoint = <&funnel_in1_in1>;
					};
				};
			};
		};

		tpdm@8a58000 {
			compatible = "qcom,coresight-tpdm", "arm,primecell";
			reg = <0x0 0x08a58000 0x0 0x1000>;

			clocks = <&rpmcc RPM_SMD_QDSS_CLK>;
			clock-names = "apb_pclk";

			label = "tpdm_west";
			qcom,dsb-element-bits = <32>;
			qcom,dsb-msrs-num = <16>;

			out-ports {
				port {
					tpdm_west_out: endpoint {
						remote-endpoint = <&tpda_center_in8>;
					};
				};
			};
		};

		cti@8b30000 {
			compatible = "arm,coresight-cti", "arm,primecell";
			reg = <0x0 0x08b30000 0x0 0x1000>;

			clocks = <&rpmcc RPM_SMD_QDSS_CLK>;
			clock-names = "apb_pclk";
			label = "cti_cortex_m3";
		};

		tpdm@8b58000 {
			compatible = "qcom,coresight-tpdm", "arm,primecell";
			reg = <0x0 0x08b58000 0x0 0x1000>;

			clocks = <&rpmcc RPM_SMD_QDSS_CLK>;
			clock-names = "apb_pclk";

			label = "tpdm_dlct";
			qcom,dsb-element-bits = <32>;
			qcom,dsb-msrs-num = <16>;

			out-ports {
				port {
					tpdm_dlct_out: endpoint {
						remote-endpoint = <&tpda_center_in2>;
					};
				};
			};
		};

		cti@8b59000 {
			compatible = "arm,coresight-cti", "arm,primecell";
			reg = <0x0 0x08b59000 0x0 0x1000>;

			clocks = <&rpmcc RPM_SMD_QDSS_CLK>;
			clock-names = "apb_pclk";
			label = "cti_dlct_0";
		};

		cti@8b5a000 {
			compatible = "arm,coresight-cti", "arm,primecell";
			reg = <0x0 0x08b5a000 0x0 0x1000>;

			clocks = <&rpmcc RPM_SMD_QDSS_CLK>;
			clock-names = "apb_pclk";
			label = "cti_dlct_1";
		};

		cti@8b5b000 {
			compatible = "arm,coresight-cti", "arm,primecell";
			reg = <0x0 0x08b5b000 0x0 0x1000>;

			clocks = <&rpmcc RPM_SMD_QDSS_CLK>;
			clock-names = "apb_pclk";
			label = "cti_dlct_2";
		};

		cti@8b5c000 {
			compatible = "arm,coresight-cti", "arm,primecell";
			reg = <0x0 0x08b5c000 0x0 0x1000>;

			clocks = <&rpmcc RPM_SMD_QDSS_CLK>;
			clock-names = "apb_pclk";
			label = "cti_dlct_3";
		};

		tpdm@8b60000 {
			compatible = "qcom,coresight-tpdm", "arm,primecell";
			reg = <0x0 0x08b60000 0x0 0x1000>;

			clocks = <&rpmcc RPM_SMD_QDSS_CLK>;
			clock-names = "apb_pclk";

			label = "tpdm_ddr";
			qcom,cmb-element-bits = <32>;
			qcom,cmb-msrs-num = <1>;
			qcom,dsb-element-bits = <32>;
			qcom,dsb-msrs-num = <32>;

			out-ports {
				port {
					tpdm_ddr_out: endpoint {
						remote-endpoint = <&funnel_ddr_in0>;
					};
				};
			};
		};

		cti@8b62000 {
			compatible = "arm,coresight-cti", "arm,primecell";
			reg = <0x0 0x08b62000 0x0 0x1000>;

			clocks = <&rpmcc RPM_SMD_QDSS_CLK>;
			clock-names = "apb_pclk";
			label = "cti_ddr_dl_0";
		};

		funnel@8b65000 {
			compatible = "arm,coresight-dynamic-funnel", "arm,primecell";
			reg = <0x0 0x08b65000 0x0 0x1000>;

			clocks = <&rpmcc RPM_SMD_QDSS_CLK>;
			clock-names = "apb_pclk";

			in-ports {
				#address-cells = <1>;
				#size-cells = <0>;

				port@0 {
					reg = <0>;

					funnel_ddr_in0: endpoint {
						remote-endpoint = <&tpdm_ddr_out>;
					};
				};
			};

			out-ports {
				port {
					funnel_ddr_out0: endpoint {
						remote-endpoint = <&tpda_center_in4>;
					};
				};
			};
		};

		cti@8b70000 {
			compatible = "arm,coresight-cti", "arm,primecell";
			reg = <0x0 0x08b70000 0x0 0x1000>;

			clocks = <&rpmcc RPM_SMD_QDSS_CLK>;
			clock-names = "apb_pclk";
			label = "cti_ddr_dl_0_1";
		};

		cti@8b71000 {
			compatible = "arm,coresight-cti", "arm,primecell";
			reg = <0x0 0x08b71000 0x0 0x1000>;

			clocks = <&rpmcc RPM_SMD_QDSS_CLK>;
			clock-names = "apb_pclk";
			label = "cti_ddr_dl_1_1";
		};

		cti@9020000 {
			compatible = "arm,coresight-cti", "arm,primecell";
			reg = <0x0 0x09020000 0x0 0x1000>;

			clocks = <&rpmcc RPM_SMD_QDSS_CLK>;
			clock-names = "apb_pclk";
			label = "cti_apss_pe0";
		};

		etm@9040000 {
			compatible = "arm,coresight-etm4x-sysreg";
			reg = <0x0 0x09040000 0x0 0x1000>;
			cpu = <&cpu0>;
			qcom,skip-power-up;

			out-ports {
				port {
					etm0_out: endpoint {
						remote-endpoint = <&funnel_cpuss0_in0>;
					};
				};
			};
		};

		cti@90e0000 {
			compatible = "arm,coresight-cti", "arm,primecell";
			reg = <0x0 0x090e0000 0x0 0x1000>;

			clocks = <&rpmcc RPM_SMD_QDSS_CLK>;
			clock-names = "apb_pclk";
			label = "cti_apss_cluster";
		};

		cti@9120000 {
			compatible = "arm,coresight-cti", "arm,primecell";
			reg = <0x0 0x09120000 0x0 0x1000>;

			clocks = <&rpmcc RPM_SMD_QDSS_CLK>;
			clock-names = "apb_pclk";
			label = "cti_apss_pe1";
		};

		etm@9140000 {
			compatible = "arm,coresight-etm4x-sysreg";
			reg = <0x0 0x09140000 0x0 0x1000>;
			cpu = <&cpu1>;
			qcom,skip-power-up;

			out-ports {
				port {
					etm1_out: endpoint {
						remote-endpoint = <&funnel_cpuss0_in1>;
					};
				};
			};
		};

		cti@9220000 {
			compatible = "arm,coresight-cti", "arm,primecell";
			reg = <0x0 0x09220000 0x0 0x1000>;

			clocks = <&rpmcc RPM_SMD_QDSS_CLK>;
			clock-names = "apb_pclk";
			label = "cti_apss_pe2";
		};

		etm@9240000 {
			compatible = "arm,coresight-etm4x-sysreg";
			reg = <0x0 0x09240000 0x0 0x1000>;
			cpu = <&cpu2>;
			qcom,skip-power-up;

			out-ports {
				port {
					etm2_out: endpoint {
						remote-endpoint = <&funnel_cpuss0_in2>;
					};
				};
			};
		};

		cti@9320000 {
			compatible = "arm,coresight-cti", "arm,primecell";
			reg = <0x0 0x09320000 0x0 0x1000>;

			clocks = <&rpmcc RPM_SMD_QDSS_CLK>;
			clock-names = "apb_pclk";
			label = "cti_apss_pe3";
		};

		etm@9340000 {
			compatible = "arm,coresight-etm4x-sysreg";
			reg = <0x0 0x09340000 0x0 0x1000>;
			cpu = <&cpu3>;
			qcom,skip-power-up;

			out-ports {
				port {
					etm3_out: endpoint {
						remote-endpoint = <&funnel_cpuss0_in3>;
					};
				};
			};
		};

		funnel@9800000 {
			compatible = "arm,coresight-dynamic-funnel", "arm,primecell";
			reg = <0x0 0x09800000 0x0 0x1000>;

			clocks = <&rpmcc RPM_SMD_QDSS_CLK>;
			clock-names = "apb_pclk";

			in-ports {
				#address-cells = <1>;
				#size-cells = <0>;

				port@0 {
					reg = <0>;

					funnel_cpuss0_in0: endpoint {
						remote-endpoint = <&etm0_out>;
					};
				};

				port@1 {
					reg = <1>;

					funnel_cpuss0_in1: endpoint {
						remote-endpoint = <&etm1_out>;
					};
				};

				port@2 {
					reg = <2>;

					funnel_cpuss0_in2: endpoint {
						remote-endpoint = <&etm2_out>;
					};
				};

				port@3 {
					reg = <3>;

					funnel_cpuss0_in3: endpoint {
						remote-endpoint = <&etm3_out>;
					};
				};
			};

			out-ports {
				port {
					funnel_cpuss0_out: endpoint {
						remote-endpoint = <&funnel_cpuss1_in0>;
					};
				};
			};
		};

		funnel@9810000 {
			compatible = "arm,coresight-dynamic-funnel", "arm,primecell";
			reg = <0x0 0x09810000 0x0 0x1000>;

			clocks = <&rpmcc RPM_SMD_QDSS_CLK>;
			clock-names = "apb_pclk";

			in-ports {
				#address-cells = <1>;
				#size-cells = <0>;

				port@0 {
					reg = <0>;

					funnel_cpuss1_in0: endpoint {
						remote-endpoint = <&funnel_cpuss0_out>;
					};
				};

				port@3 {
					reg = <3>;

					funnel_cpuss1_in3: endpoint {
						remote-endpoint = <&tpda_apss_out>;
					};
				};
			};

			out-ports {
				port {
					funnel_cpuss1_out: endpoint {
						remote-endpoint = <&funnel_in1_in6>;
					};
				};
			};
		};

		cti@982b000 {
			compatible = "arm,coresight-cti", "arm,primecell";
			reg = <0x0 0x0982b000 0x0 0x1000>;

			clocks = <&rpmcc RPM_SMD_QDSS_CLK>;
			clock-names = "apb_pclk";
			label = "cti_riscv";
		};

		tpdm@9860000 {
			compatible = "qcom,coresight-tpdm", "arm,primecell";
			reg = <0x0 0x09860000 0x0 0x1000>;

			clocks = <&rpmcc RPM_SMD_QDSS_CLK>;
			clock-names = "apb_pclk";

			label = "tpdm_actpm";
			qcom,cmb-element-bits = <64>;
			qcom,cmb-msrs-num = <1>;

			out-ports {
				port {
					tpdm_actpm_out: endpoint {
						remote-endpoint = <&tpda_apss_in2>;
					};
				};
			};
		};

		tpdm@9861000 {
			compatible = "qcom,coresight-tpdm", "arm,primecell";
			reg = <0x0 0x09861000 0x0 0x1000>;

			clocks = <&rpmcc RPM_SMD_QDSS_CLK>;
			clock-names = "apb_pclk";

			label = "tpdm_hwe";
			qcom,dsb-element-bits = <32>;
			qcom,dsb-msrs-num = <32>;

			out-ports {
				port {
					tpdm_hwe_out: endpoint {
						remote-endpoint = <&tpda_apss_in3>;
					};
				};
			};
		};

		tpda@9863000 {
			compatible = "qcom,coresight-tpda", "arm,primecell";
			reg = <0x0 0x09863000 0x0 0x1000>;

			clocks = <&rpmcc RPM_SMD_QDSS_CLK>;
			clock-names = "apb_pclk";

			in-ports {
				#address-cells = <1>;
				#size-cells = <0>;

				port@0 {
					reg = <0>;

					tpda_apss_in0: endpoint {
						remote-endpoint = <&tpdm_llm_silver_out>;
					};
				};

				port@2 {
					reg = <2>;

					tpda_apss_in2: endpoint {
						remote-endpoint = <&tpdm_actpm_out>;
					};
				};

				port@3 {
					reg = <3>;

					tpda_apss_in3: endpoint {
						remote-endpoint = <&tpdm_hwe_out>;
					};
				};
			};

			out-ports {
				port {
					tpda_apss_out: endpoint {
						remote-endpoint = <&funnel_cpuss1_in3>;
					};
				};
			};
		};

		tpdm@98a0000 {
			compatible = "qcom,coresight-tpdm", "arm,primecell";
			reg = <0x0 0x098a0000 0x0 0x1000>;

			clocks = <&rpmcc RPM_SMD_QDSS_CLK>;
			clock-names = "apb_pclk";

			label = "tpdm_llm_silver";
			qcom,cmb-element-bits = <32>;
			qcom,cmb-msrs-num = <12>;

			out-ports {
				port {
					tpdm_llm_silver_out: endpoint {
						remote-endpoint = <&tpda_apss_in0>;
					};
				};
			};
		};

		cti@98e0000 {
			compatible = "arm,coresight-cti", "arm,primecell";
			reg = <0x0 0x098e0000 0x0 0x1000>;

			clocks = <&rpmcc RPM_SMD_QDSS_CLK>;
			clock-names = "apb_pclk";
			label = "cti_apss_0";
		};

		cti@98f0000 {
			compatible = "arm,coresight-cti", "arm,primecell";
			reg = <0x0 0x098f0000 0x0 0x1000>;

			clocks = <&rpmcc RPM_SMD_QDSS_CLK>;
			clock-names = "apb_pclk";
			label = "cti_apss_1";
		};

		cti@9900000 {
			compatible = "arm,coresight-cti", "arm,primecell";
			reg = <0x0 0x09900000 0x0 0x1000>;

			clocks = <&rpmcc RPM_SMD_QDSS_CLK>;
			clock-names = "apb_pclk";
			label = "cti_apss_2";
		};

		remoteproc_cdsp: remoteproc@b300000 {
			compatible = "qcom,shikra-cdsp-pas";
			reg = <0x0 0x0b300000 0x0 0x100000>;

			interrupts-extended = <&intc GIC_SPI 265 IRQ_TYPE_EDGE_RISING>,
					      <&cdsp_smp2p_in 0 IRQ_TYPE_EDGE_RISING>,
					      <&cdsp_smp2p_in 1 IRQ_TYPE_EDGE_RISING>,
					      <&cdsp_smp2p_in 2 IRQ_TYPE_EDGE_RISING>,
					      <&cdsp_smp2p_in 3 IRQ_TYPE_EDGE_RISING>,
					      <&cdsp_smp2p_in 7 IRQ_TYPE_EDGE_RISING>;
			interrupt-names = "wdog",
					  "fatal",
					  "ready",
					  "handover",
					  "stop-ack",
					  "shutdown-ack";

			clocks = <&rpmcc RPM_SMD_XO_CLK_SRC>;
			clock-names = "xo";

			interconnects = <&mem_noc MASTER_AMPSS_M0 RPM_ALWAYS_TAG
					 &mc_virt SLAVE_EBI_CH0 RPM_ALWAYS_TAG>,
					<&system_noc MASTER_CRYPTO_CORE0 RPM_ALWAYS_TAG
					 &mc_virt SLAVE_EBI_CH0 RPM_ALWAYS_TAG>;

			power-domains = <&rpmpd RPMHPD_CX>;

			memory-region = <&cdsp_mem>;

			qcom,smem-states = <&cdsp_smp2p_out 0>;
			qcom,smem-state-names = "stop";

			status = "disabled";

			glink-edge {
				interrupts = <GIC_SPI 261 IRQ_TYPE_EDGE_RISING>;
				mboxes = <&apcs_glb 4>;
				qcom,remote-pid = <5>;
				label = "cdsp";

				fastrpc {
					compatible = "qcom,fastrpc";
					#address-cells = <1>;
					#size-cells = <0>;
					label = "cdsp";
					qcom,glink-channels = "fastrpcglink-apps-dsp";

					compute-cb@1 {
						compatible = "qcom,fastrpc-compute-cb";
						reg = <1>;
						iommus = <&apps_smmu 0x0201 0x0000>;
					};

					compute-cb@2 {
						compatible = "qcom,fastrpc-compute-cb";
						reg = <2>;
						iommus = <&apps_smmu 0x0202 0x0000>;
					};

					compute-cb@3 {
						compatible = "qcom,fastrpc-compute-cb";
						reg = <3>;
						iommus = <&apps_smmu 0x0203 0x0000>;
					};

					compute-cb@4 {
						compatible = "qcom,fastrpc-compute-cb";
						reg = <4>;
						iommus = <&apps_smmu 0x0204 0x0000>;
					};

					compute-cb@5 {
						compatible = "qcom,fastrpc-compute-cb";
						reg = <5>;
						iommus = <&apps_smmu 0x0205 0x0000>;
					};

					compute-cb@6 {
						compatible = "qcom,fastrpc-compute-cb";
						reg = <6>;
						iommus = <&apps_smmu 0x0206 0x0000>;
					};

					compute-cb@9 {
						compatible = "qcom,fastrpc-compute-cb";
						reg = <9>;
						iommus = <&apps_smmu 0x0209 0x0000>;
					};
				};
			};
		};

		remoteproc_lpaicp: remoteproc@b800000 {
			compatible = "qcom,shikra-lpaicp-pas";
			reg = <0x0 0x0b800000 0x0 0x200000>;

			interrupts-extended = <&intc GIC_SPI 257 IRQ_TYPE_EDGE_RISING>,
					      <&lmcu_smp2p_in 0 IRQ_TYPE_NONE>,
					      <&lmcu_smp2p_in 1 IRQ_TYPE_NONE>,
					      <&lmcu_smp2p_in 2 IRQ_TYPE_NONE>,
					      <&lmcu_smp2p_in 3 IRQ_TYPE_NONE>;

			interrupt-names = "wdog",
					  "fatal",
					  "ready",
					  "handover",
					  "stop-ack";

			clocks = <&rpmcc RPM_SMD_XO_CLK_SRC>;
			clock-names = "xo";

			memory-region = <&lmcu_mem &lmcu_dtb_mem>;

			qcom,smem-states = <&lmcu_smp2p_out 0>;
			qcom,smem-state-names = "stop";

			status = "disabled";

			glink-edge {
				interrupts = <GIC_SPI 286 IRQ_TYPE_EDGE_RISING>;
				mboxes = <&apcs_glb 9>;
				qcom,remote-pid = <26>;
				label = "lpaicp";
			};
		};

		cpufreq_hw: cpufreq@fd91000 {
			compatible = "qcom,shikra-cpufreq-rimps", "qcom,cpufreq-rimps";
			reg = <0x0 0x0fd91000 0x0 0x1000>,
			      <0x0 0x0fd92000 0x0 0x1000>;
			reg-names = "freq-domain0",
				    "freq-domain1";

			clocks = <&rpmcc RPM_SMD_XO_CLK_SRC>, <&gcc GPLL0>;
			clock-names = "xo", "alternate";

			interrupts = <GIC_SPI 30 IRQ_TYPE_LEVEL_HIGH>,
				     <GIC_SPI 31 IRQ_TYPE_LEVEL_HIGH>;
			interrupt-names = "dcvsh-irq-0",
					  "dcvsh-irq-1";

			#freq-domain-cells = <1>;
		};
	};

	snoc {
		compatible = "arm,coresight-dummy-source";
		arm,static-trace-id = <18>;

		label = "snoc";

		out-ports {
			port {
				snoc_out: endpoint {
					remote-endpoint = <&funnel_in0_in5>;
				};
			};
		};
	};

	thermal_zones: thermal-zones {
		aoss0-thermal {
			thermal-sensors = <&tsens0 0>;

			trips {
				trip-point0 {
					temperature = <110000>;
					hysteresis = <5000>;
					type = "hot";
				};

				aoss0-critical {
					temperature = <115000>;
					hysteresis = <0>;
					type = "critical";
				};
			};
		};

		cpu-0-0-thermal {
			thermal-sensors = <&tsens0 1>;

			trips {
				trip-point0 {
					temperature = <110000>;
					hysteresis = <5000>;
					type = "hot";
				};

				cpu00-critical {
					temperature = <115000>;
					hysteresis = <0>;
					type = "critical";
				};
			};
		};

		cpu-0-1-thermal {
			thermal-sensors = <&tsens0 2>;

			trips {
				trip-point0 {
					temperature = <110000>;
					hysteresis = <5000>;
					type = "hot";
				};

				cpu01-critical {
					temperature = <115000>;
					hysteresis = <0>;
					type = "critical";
				};
			};
		};

		cpu-1-0-thermal {
			thermal-sensors = <&tsens0 3>;

			trips {
				trip-point0 {
					temperature = <110000>;
					hysteresis = <5000>;
					type = "hot";
				};

				cpu10-critical {
					temperature = <115000>;
					hysteresis = <0>;
					type = "critical";
				};
			};
		};

		cpu-1-1-thermal {
			thermal-sensors = <&tsens0 4>;

			trips {
				trip-point0 {
					temperature = <110000>;
					hysteresis = <5000>;
					type = "hot";
				};

				cpu11-critical {
					temperature = <115000>;
					hysteresis = <0>;
					type = "critical";
				};
			};
		};

		cpuss0-thermal {
			thermal-sensors = <&tsens0 5>;

			trips {
				trip-point0 {
					temperature = <110000>;
					hysteresis = <5000>;
					type = "hot";
				};

				cpuss0-critical {
					temperature = <115000>;
					hysteresis = <0>;
					type = "critical";
				};
			};
		};

		gpuss-thermal {
			thermal-sensors = <&tsens0 6>;

			trips {
				trip-point0 {
					temperature = <110000>;
					hysteresis = <5000>;
					type = "hot";
				};

				gpuss-critical {
					temperature = <115000>;
					hysteresis = <0>;
					type = "critical";
				};
			};
		};

		nsp-thermal {
			thermal-sensors = <&tsens0 7>;

			trips {
				trip-point0 {
					temperature = <110000>;
					hysteresis = <5000>;
					type = "hot";
				};

				nsp-critical {
					temperature = <115000>;
					hysteresis = <0>;
					type = "critical";
				};
			};
		};

		mdmss0-thermal {
			thermal-sensors = <&tsens0 8>;

			trips {
				trip-point0 {
					temperature = <110000>;
					hysteresis = <5000>;
					type = "hot";
				};

				mdmss0-critical {
					temperature = <115000>;
					hysteresis = <0>;
					type = "critical";
				};
			};
		};

		mdmss1-thermal {
			thermal-sensors = <&tsens0 9>;

			trips {
				trip-point0 {
					temperature = <110000>;
					hysteresis = <5000>;
					type = "hot";
				};

				mdmss1-critical {
					temperature = <115000>;
					hysteresis = <0>;
					type = "critical";
				};
			};
		};

		camera-thermal {
			thermal-sensors = <&tsens0 10>;

			trips {
				trip-point0 {
					temperature = <110000>;
					hysteresis = <5000>;
					type = "hot";
				};

				camera-critical {
					temperature = <115000>;
					hysteresis = <0>;
					type = "critical";
				};
			};
		};

		video-thermal {
			thermal-sensors = <&tsens0 11>;

			trips {
				trip-point0 {
					temperature = <110000>;
					hysteresis = <5000>;
					type = "hot";
				};

				video-critical {
					temperature = <115000>;
					hysteresis = <0>;
					type = "critical";
				};
			};
		};

		cpu-0-2-thermal {
			thermal-sensors = <&tsens0 12>;

			trips {
				trip-point0 {
					temperature = <110000>;
					hysteresis = <5000>;
					type = "hot";
				};

				cpu02-critical {
					temperature = <115000>;
					hysteresis = <0>;
					type = "critical";
				};
			};
		};

		cpuss1-thermal {
			thermal-sensors = <&tsens0 13>;

			trips {
				trip-point0 {
					temperature = <110000>;
					hysteresis = <5000>;
					type = "hot";
				};

				cpuss1-critical {
					temperature = <115000>;
					hysteresis = <0>;
					type = "critical";
				};
			};
		};
	};

	timer {
		compatible = "arm,armv8-timer";

		interrupts = <GIC_PPI 1 IRQ_TYPE_LEVEL_LOW>,
			     <GIC_PPI 2 IRQ_TYPE_LEVEL_LOW>,
			     <GIC_PPI 3 IRQ_TYPE_LEVEL_LOW>,
			     <GIC_PPI 0 IRQ_TYPE_LEVEL_LOW>;
	};
};
